AUTOSAR XML (schema 00053)
package /MICROSAR/Dcm_swc
  mode declaration group DcmEcuReset: category=EXPLICIT_ORDER, initial-mode=NONE, on-transition-value=7
    7 x mode:
      NONE: value=0
      HARD: value=1
      KEYONOFF: value=2
      SOFT: value=3
      JUMPTOBOOTLOADER: value=4
      JUMPTOSYSSUPPLIERBOOTLOADER: value=5
      EXECUTE: value=6
  mode declaration group DcmDiagnosticSessionControl: category=EXPLICIT_ORDER, initial-mode=DEFAULT_SESSION, on-transition-value=255
    mode DEFAULT_SESSION: value=1
    mode PROGRAMMING_SESSION: value=2
    mode EXTENDED_SESSION: value=3
  mode declaration group DcmCommunicationControl: category=EXPLICIT_ORDER, initial-mode=DCM_ENABLE_RX_TX_NORM, on-transition-value=12
    12 x mode:
      DCM_ENABLE_RX_TX_NORM: value=0
      DCM_ENABLE_RX_DISABLE_TX_NORM: value=1
      DCM_DISABLE_RX_ENABLE_TX_NORM: value=2
      DCM_DISABLE_RX_TX_NORMAL: value=3
      DCM_ENABLE_RX_TX_NM: value=4
      DCM_ENABLE_RX_DISABLE_TX_NM: value=5
      DCM_DISABLE_RX_ENABLE_TX_NM: value=6
      DCM_DISABLE_RX_TX_NM: value=7
      DCM_ENABLE_RX_TX_NORM_NM: value=8
      DCM_ENABLE_RX_DISABLE_TX_NORM_NM: value=9
      DCM_DISABLE_RX_ENABLE_TX_NORM_NM: value=10
      DCM_DISABLE_RX_TX_NORM_NM: value=11
  data type mapping set DcmMappingSet  # Contains mapping for ModeDeclarationGroups and data types which are provided by Dcm.
    mode-request-type-maps:
      implementation-data-type=Dcm_ControlDtcSettingType, mode-group=DcmControlDtcSetting
      implementation-data-type=Dcm_EcuResetType, mode-group=DcmEcuReset
      implementation-data-type=Dcm_DiagnosticSessionControlType, mode-group=DcmDiagnosticSessionControl
      implementation-data-type=Dcm_CommunicationModeType, mode-group=DcmCommunicationControl
package /MICROSAR/Dcm_swc/Interfaces
  mode switch interface DcmEcuReset: is-service=true, service-kind=DIAGNOSTIC-COMMUNICATION-MANAGER
    mode group DcmEcuReset: type=DcmEcuReset
  mode switch interface DcmDiagnosticSessionControl: is-service=true, service-kind=DIAGNOSTIC-COMMUNICATION-MANAGER
    mode group DcmDiagnosticSessionControl: type=DcmDiagnosticSessionControl
  mode switch interface DcmCommunicationControl_ComMConf_ComMChannel_CN_PCAN_RADAR_458ff0f1: is-service=true, service-kind=DIAGNOSTIC-COMMUNICATION-MANAGER
    mode group DcmCommunicationControl_ComMConf_ComMChannel_CN_PCAN_RADAR_458ff0f1: type=DcmCommunicationControl
  42 x client server interface, all with is-service=true, service-kind=DIAGNOSTIC-COMMUNICATION-MANAGER:
    DCMServices
      6 x operation:
        GetActiveProtocol: possible-error=E_OK
          arg ActiveProtocol: type=Dcm_ProtocolType, direction=OUT
        GetSesCtrlType: possible-error=E_OK
          arg SesCtrlType: type=Dcm_SesCtrlType, direction=OUT
        ResetToDefaultSession: possible-error=E_OK
        GetSecurityLevel: possible-error=E_OK
          arg SecLevel: type=Dcm_SecLevelType, direction=OUT
        SetActiveDiagnostic: possible-error=E_OK
          arg active: type=boolean, direction=IN
        GetRequestKind: possible-error=DCMServices/E_NOT_OK
          arg TesterSourceAddress: type=uint16, direction=IN
          arg RequestKind: type=Dcm_RequestKindType, direction=OUT
      error E_OK: error-code=0
      error E_NOT_OK: error-code=1
    SecurityAccess_UnlockedL1
      4 x operation:
        GetSeed: possible-error=[SecurityAccess_UnlockedL1/E_NOT_OK, SecurityAccess_UnlockedL1/DCM_E_PENDING]
          arg OpStatus: type=Dcm_OpStatusType, direction=IN
          arg Seed: type=Dcm_Data16ByteType, direction=OUT
          arg ErrorCode: type=Dcm_NegativeResponseCodeType, direction=OUT
        CompareKey: possible-error=[SecurityAccess_UnlockedL1/E_NOT_OK, SecurityAccess_UnlockedL1/DCM_E_PENDING, DCM_E_COMPARE_KEY_FAILED]
          arg Key: type=Dcm_Data16ByteType, direction=IN
          arg OpStatus: type=Dcm_OpStatusType, direction=IN
          arg ErrorCode: type=Dcm_NegativeResponseCodeType, direction=OUT
        GetSecurityAttemptCounter: possible-error=[SecurityAccess_UnlockedL1/E_NOT_OK, SecurityAccess_UnlockedL1/DCM_E_PENDING]
          arg OpStatus: type=Dcm_OpStatusType, direction=IN
          arg AttemptCounter: type=uint8, direction=OUT
        SetSecurityAttemptCounter: possible-error=[SecurityAccess_UnlockedL1/E_NOT_OK, SecurityAccess_UnlockedL1/DCM_E_PENDING]
          arg OpStatus: type=Dcm_OpStatusType, direction=IN
          arg AttemptCounter: type=uint8, direction=IN
      error E_NOT_OK: error-code=1
      error DCM_E_PENDING: error-code=10
      error DCM_E_COMPARE_KEY_FAILED: error-code=11
    DataServices_Data_VIN_Read
      operation ReadData: possible-error=[DataServices_Data_VIN_Read/E_NOT_OK, DataServices_Data_VIN_Read/DCM_E_PENDING]
        arg OpStatus: type=Dcm_OpStatusType, direction=IN
        arg Data: type=Dcm_DataElement_Data_VIN_ReadType, direction=OUT
      operation ConditionCheckRead: possible-error=[DataServices_Data_VIN_Read/E_NOT_OK, DataServices_Data_VIN_Read/DCM_E_PENDING]
        arg OpStatus: type=Dcm_OpStatusType, direction=IN
        arg ErrorCode: type=Dcm_NegativeResponseCodeType, direction=OUT
      operation WriteData: possible-error=[DataServices_Data_VIN_Read/E_NOT_OK, DataServices_Data_VIN_Read/DCM_E_PENDING]
        arg Data: type=Dcm_DataElement_Data_VIN_ReadType, direction=IN
        arg OpStatus: type=Dcm_OpStatusType, direction=IN
        arg ErrorCode: type=Dcm_NegativeResponseCodeType, direction=OUT
      error E_NOT_OK: error-code=1
      error DCM_E_PENDING: error-code=10
    RoutineServices_Routine_CheckProgPreCond_Start
      operation Start: possible-error=[RoutineServices_Routine_CheckProgPreCond_Start/E_NOT_OK, RoutineServices_Routine_CheckProgPreCond_Start/DCM_E_PENDING, RoutineServices_Routine_CheckProgPreCond_Start/DCM_E_FORCE_RCRRP]
        arg OpStatus: type=Dcm_OpStatusType, direction=IN
        arg Out_ResData: type=Dcm_StartDataOut_Routine_CheckProgPreCond_Start_Out_ResDataType, direction=OUT
        arg ErrorCode: type=Dcm_NegativeResponseCodeType, direction=OUT
      error E_NOT_OK: error-code=1
      error DCM_E_PENDING: error-code=10
      error DCM_E_FORCE_RCRRP: error-code=12
    RoutineServices_Routine_CheckSig_Start
      operation Start: possible-error=[RoutineServices_Routine_CheckSig_Start/E_NOT_OK, RoutineServices_Routine_CheckSig_Start/DCM_E_PENDING, RoutineServices_Routine_CheckSig_Start/DCM_E_FORCE_RCRRP]
        arg OpStatus: type=Dcm_OpStatusType, direction=IN
        arg Out_ResData: type=Dcm_StartDataOut_Routine_CheckSig_Start_Out_ResDataType, direction=OUT
        arg ErrorCode: type=Dcm_NegativeResponseCodeType, direction=OUT
      error E_NOT_OK: error-code=1
      error DCM_E_PENDING: error-code=10
      error DCM_E_FORCE_RCRRP: error-code=12
    RoutineServices_Routine_Static_Alignment_Execution_Start
      operation Start: possible-error=[RoutineServices_Routine_Static_Alignment_Execution_Start/E_NOT_OK, RoutineServices_Routine_Static_Alignment_Execution_Start/DCM_E_PENDING, RoutineServices_Routine_Static_Alignment_Execution_Start/DCM_E_FORCE_RCRRP]
        arg OpStatus: type=Dcm_OpStatusType, direction=IN
        arg ErrorCode: type=Dcm_NegativeResponseCodeType, direction=OUT
      operation Stop: possible-error=[RoutineServices_Routine_Static_Alignment_Execution_Start/E_NOT_OK, RoutineServices_Routine_Static_Alignment_Execution_Start/DCM_E_PENDING, RoutineServices_Routine_Static_Alignment_Execution_Start/DCM_E_FORCE_RCRRP]
        arg OpStatus: type=Dcm_OpStatusType, direction=IN
        arg ErrorCode: type=Dcm_NegativeResponseCodeType, direction=OUT
      operation RequestResults: possible-error=[RoutineServices_Routine_Static_Alignment_Execution_Start/E_NOT_OK, RoutineServices_Routine_Static_Alignment_Execution_Start/DCM_E_PENDING, RoutineServices_Routine_Static_Alignment_Execution_Start/DCM_E_FORCE_RCRRP]
        arg OpStatus: type=Dcm_OpStatusType, direction=IN
        arg Out_ResData: type=Dcm_RequestDataOut_Routine_Static_Alignment_Execution_Start_Out_ResDataType, direction=OUT
        arg ErrorCode: type=Dcm_NegativeResponseCodeType, direction=OUT
      error E_NOT_OK: error-code=1
      error DCM_E_PENDING: error-code=10
      error DCM_E_FORCE_RCRRP: error-code=12
    RoutineServices_Routine_Service_Alignment_Execution_Start
      operation Start: possible-error=[RoutineServices_Routine_Service_Alignment_Execution_Start/E_NOT_OK, RoutineServices_Routine_Service_Alignment_Execution_Start/DCM_E_PENDING, RoutineServices_Routine_Service_Alignment_Execution_Start/DCM_E_FORCE_RCRRP]
        arg OpStatus: type=Dcm_OpStatusType, direction=IN
        arg ErrorCode: type=Dcm_NegativeResponseCodeType, direction=OUT
      operation Stop: possible-error=[RoutineServices_Routine_Service_Alignment_Execution_Start/E_NOT_OK, RoutineServices_Routine_Service_Alignment_Execution_Start/DCM_E_PENDING, RoutineServices_Routine_Service_Alignment_Execution_Start/DCM_E_FORCE_RCRRP]
        arg OpStatus: type=Dcm_OpStatusType, direction=IN
        arg ErrorCode: type=Dcm_NegativeResponseCodeType, direction=OUT
      operation RequestResults: possible-error=[RoutineServices_Routine_Service_Alignment_Execution_Start/E_NOT_OK, RoutineServices_Routine_Service_Alignment_Execution_Start/DCM_E_PENDING, RoutineServices_Routine_Service_Alignment_Execution_Start/DCM_E_FORCE_RCRRP]
        arg OpStatus: type=Dcm_OpStatusType, direction=IN
        arg Out_ResData: type=Dcm_RequestDataOut_Routine_Service_Alignment_Execution_Start_Out_ResDataType, direction=OUT
        arg ErrorCode: type=Dcm_NegativeResponseCodeType, direction=OUT
      error E_NOT_OK: error-code=1
      error DCM_E_PENDING: error-code=10
      error DCM_E_FORCE_RCRRP: error-code=12
    RoutineServices_Routine_Pin_Position_Lock_Start
      operation Start: possible-error=[RoutineServices_Routine_Pin_Position_Lock_Start/E_NOT_OK, RoutineServices_Routine_Pin_Position_Lock_Start/DCM_E_PENDING, RoutineServices_Routine_Pin_Position_Lock_Start/DCM_E_FORCE_RCRRP]
        4 x arg:
          In_ReqData: type=Dcm_StartDataIn_Routine_Pin_Position_Lock_Start_In_ReqDataType, direction=IN
          OpStatus: type=Dcm_OpStatusType, direction=IN
          Out_ResData: type=Dcm_StartDataOut_Routine_Pin_Position_Lock_Start_Out_ResDataType, direction=OUT
          ErrorCode: type=Dcm_NegativeResponseCodeType, direction=OUT
      operation RequestResults: possible-error=[RoutineServices_Routine_Pin_Position_Lock_Start/E_NOT_OK, RoutineServices_Routine_Pin_Position_Lock_Start/DCM_E_PENDING, RoutineServices_Routine_Pin_Position_Lock_Start/DCM_E_FORCE_RCRRP]
        arg OpStatus: type=Dcm_OpStatusType, direction=IN
        arg Out_ResData: type=Dcm_RequestDataOut_Routine_Pin_Position_Lock_Start_Out_ResDataType, direction=OUT
        arg ErrorCode: type=Dcm_NegativeResponseCodeType, direction=OUT
      error E_NOT_OK: error-code=1
      error DCM_E_PENDING: error-code=10
      error DCM_E_FORCE_RCRRP: error-code=12
    RoutineServices_Routine_Pin_Position_Unlock_Start
      operation Start: possible-error=[RoutineServices_Routine_Pin_Position_Unlock_Start/E_NOT_OK, RoutineServices_Routine_Pin_Position_Unlock_Start/DCM_E_PENDING, RoutineServices_Routine_Pin_Position_Unlock_Start/DCM_E_FORCE_RCRRP]
        4 x arg:
          In_ReqData: type=Dcm_StartDataIn_Routine_Pin_Position_Unlock_Start_In_ReqDataType, direction=IN
          OpStatus: type=Dcm_OpStatusType, direction=IN
          Out_ResData: type=Dcm_StartDataOut_Routine_Pin_Position_Unlock_Start_Out_ResDataType, direction=OUT
          ErrorCode: type=Dcm_NegativeResponseCodeType, direction=OUT
      operation RequestResults: possible-error=[RoutineServices_Routine_Pin_Position_Unlock_Start/E_NOT_OK, RoutineServices_Routine_Pin_Position_Unlock_Start/DCM_E_PENDING, RoutineServices_Routine_Pin_Position_Unlock_Start/DCM_E_FORCE_RCRRP]
        arg OpStatus: type=Dcm_OpStatusType, direction=IN
        arg Out_ResData: type=Dcm_RequestDataOut_Routine_Pin_Position_Unlock_Start_Out_ResDataType, direction=OUT
        arg ErrorCode: type=Dcm_NegativeResponseCodeType, direction=OUT
      error E_NOT_OK: error-code=1
      error DCM_E_PENDING: error-code=10
      error DCM_E_FORCE_RCRRP: error-code=12
    RoutineServices_Routine_EraseMem_Start
      operation Start: possible-error=[RoutineServices_Routine_EraseMem_Start/E_NOT_OK, RoutineServices_Routine_EraseMem_Start/DCM_E_PENDING, RoutineServices_Routine_EraseMem_Start/DCM_E_FORCE_RCRRP]
        4 x arg:
          In_ReqData: type=Dcm_StartDataIn_Routine_EraseMem_Start_In_ReqDataType, direction=IN
          OpStatus: type=Dcm_OpStatusType, direction=IN
          Out_ResData: type=Dcm_StartDataOut_Routine_EraseMem_Start_Out_ResDataType, direction=OUT
          ErrorCode: type=Dcm_NegativeResponseCodeType, direction=OUT
      error E_NOT_OK: error-code=1
      error DCM_E_PENDING: error-code=10
      error DCM_E_FORCE_RCRRP: error-code=12
    RoutineServices_Routine_CheckProgDep_Start
      operation Start: possible-error=[RoutineServices_Routine_CheckProgDep_Start/E_NOT_OK, RoutineServices_Routine_CheckProgDep_Start/DCM_E_PENDING, RoutineServices_Routine_CheckProgDep_Start/DCM_E_FORCE_RCRRP]
        arg OpStatus: type=Dcm_OpStatusType, direction=IN
        arg Out_ResData: type=Dcm_StartDataOut_Routine_CheckProgDep_Start_Out_ResDataType, direction=OUT
        arg ErrorCode: type=Dcm_NegativeResponseCodeType, direction=OUT
      error E_NOT_OK: error-code=1
      error DCM_E_PENDING: error-code=10
      error DCM_E_FORCE_RCRRP: error-code=12
    DataServices_Data_ECUBuildDate_Read
      operation ReadData: possible-error=[DataServices_Data_ECUBuildDate_Read/E_NOT_OK, DataServices_Data_ECUBuildDate_Read/DCM_E_PENDING]
        arg OpStatus: type=Dcm_OpStatusType, direction=IN
        arg Data: type=Dcm_DataElement_Data_ECUBuildDate_ReadType, direction=OUT
      operation ConditionCheckRead: possible-error=[DataServices_Data_ECUBuildDate_Read/E_NOT_OK, DataServices_Data_ECUBuildDate_Read/DCM_E_PENDING]
        arg OpStatus: type=Dcm_OpStatusType, direction=IN
        arg ErrorCode: type=Dcm_NegativeResponseCodeType, direction=OUT
      error E_NOT_OK: error-code=1
      error DCM_E_PENDING: error-code=10
    DataServices_Data_Static_Alignment_Engineering_Write_Configuration_Parameter_Write
      operation WriteData: possible-error=[DataServices_Data_Static_Alignment_Engineering_Write_Configuration_Parameter_Write/E_NOT_OK, DataServices_Data_Static_Alignment_Engineering_Write_Configuration_Parameter_Write/DCM_E_PENDING]
        arg Data: type=Dcm_DataElement_Data_Static_Alignment_Engineering_Write_Configuration_Parameter_WriteType, direction=IN
        arg OpStatus: type=Dcm_OpStatusType, direction=IN
        arg ErrorCode: type=Dcm_NegativeResponseCodeType, direction=OUT
      error E_NOT_OK: error-code=1
      error DCM_E_PENDING: error-code=10
    DataServices_Data_CANDBMatrixVer_Read
      operation ReadData: possible-error=[DataServices_Data_CANDBMatrixVer_Read/E_NOT_OK, DataServices_Data_CANDBMatrixVer_Read/DCM_E_PENDING]
        arg OpStatus: type=Dcm_OpStatusType, direction=IN
        arg Data: type=Dcm_DataElement_Data_CANDBMatrixVer_ReadType, direction=OUT
      operation ConditionCheckRead: possible-error=[DataServices_Data_CANDBMatrixVer_Read/E_NOT_OK, DataServices_Data_CANDBMatrixVer_Read/DCM_E_PENDING]
        arg OpStatus: type=Dcm_OpStatusType, direction=IN
        arg ErrorCode: type=Dcm_NegativeResponseCodeType, direction=OUT
      error E_NOT_OK: error-code=1
      error DCM_E_PENDING: error-code=10
    DataServices_Data_Service_Alignment_Engineering_Non_Configuration_Parameters_Read
      operation ReadData: possible-error=[DataServices_Data_Service_Alignment_Engineering_Non_Configuration_Parameters_Read/E_NOT_OK, DataServices_Data_Service_Alignment_Engineering_Non_Configuration_Parameters_Read/DCM_E_PENDING]
        arg OpStatus: type=Dcm_OpStatusType, direction=IN
        arg Data: type=Dcm_DataElement_Data_Service_Alignment_Engineering_Non_Configuration_Parameters_ReadType, direction=OUT
      operation ConditionCheckRead: possible-error=[DataServices_Data_Service_Alignment_Engineering_Non_Configuration_Parameters_Read/E_NOT_OK, DataServices_Data_Service_Alignment_Engineering_Non_Configuration_Parameters_Read/DCM_E_PENDING]
        arg OpStatus: type=Dcm_OpStatusType, direction=IN
        arg ErrorCode: type=Dcm_NegativeResponseCodeType, direction=OUT
      error E_NOT_OK: error-code=1
      error DCM_E_PENDING: error-code=10
    DataServices_Data_Sensor_Availability_Flag_Read
      operation ReadData: possible-error=[DataServices_Data_Sensor_Availability_Flag_Read/E_NOT_OK, DataServices_Data_Sensor_Availability_Flag_Read/DCM_E_PENDING]
        arg OpStatus: type=Dcm_OpStatusType, direction=IN
        arg Data: type=Dcm_DataElement_Data_Sensor_Availability_Flag_ReadType, direction=OUT
      operation ConditionCheckRead: possible-error=[DataServices_Data_Sensor_Availability_Flag_Read/E_NOT_OK, DataServices_Data_Sensor_Availability_Flag_Read/DCM_E_PENDING]
        arg OpStatus: type=Dcm_OpStatusType, direction=IN
        arg ErrorCode: type=Dcm_NegativeResponseCodeType, direction=OUT
      error E_NOT_OK: error-code=1
      error DCM_E_PENDING: error-code=10
    DataServices_Data_Read_Active_Fault_Table_Read
      operation ReadData: possible-error=[DataServices_Data_Read_Active_Fault_Table_Read/E_NOT_OK, DataServices_Data_Read_Active_Fault_Table_Read/DCM_E_PENDING]
        arg OpStatus: type=Dcm_OpStatusType, direction=IN
        arg Data: type=Dcm_DataElement_Data_Read_Active_Fault_Table_ReadType, direction=OUT
      operation ConditionCheckRead: possible-error=[DataServices_Data_Read_Active_Fault_Table_Read/E_NOT_OK, DataServices_Data_Read_Active_Fault_Table_Read/DCM_E_PENDING]
        arg OpStatus: type=Dcm_OpStatusType, direction=IN
        arg ErrorCode: type=Dcm_NegativeResponseCodeType, direction=OUT
      error E_NOT_OK: error-code=1
      error DCM_E_PENDING: error-code=10
    DataServices_Data_Static_Alignment_Engineering_Non_Configuration_Parameters_Read
      operation ReadData: possible-error=[DataServices_Data_Static_Alignment_Engineering_Non_Configuration_Parameters_Read/E_NOT_OK, DataServices_Data_Static_Alignment_Engineering_Non_Configuration_Parameters_Read/DCM_E_PENDING]
        arg OpStatus: type=Dcm_OpStatusType, direction=IN
        arg Data: type=Dcm_DataElement_Data_Static_Alignment_Engineering_Non_Configuration_Parameters_ReadType, direction=OUT
      operation ConditionCheckRead: possible-error=[DataServices_Data_Static_Alignment_Engineering_Non_Configuration_Parameters_Read/E_NOT_OK, DataServices_Data_Static_Alignment_Engineering_Non_Configuration_Parameters_Read/DCM_E_PENDING]
        arg OpStatus: type=Dcm_OpStatusType, direction=IN
        arg ErrorCode: type=Dcm_NegativeResponseCodeType, direction=OUT
      error E_NOT_OK: error-code=1
      error DCM_E_PENDING: error-code=10
    DataServices_Data_Dataset_Part_No_and_Revision_Read
      operation ReadData: possible-error=[DataServices_Data_Dataset_Part_No_and_Revision_Read/E_NOT_OK, DataServices_Data_Dataset_Part_No_and_Revision_Read/DCM_E_PENDING]
        arg OpStatus: type=Dcm_OpStatusType, direction=IN
        arg Data: type=Dcm_DataElement_Data_Dataset_Part_No_and_Revision_ReadType, direction=OUT
      operation ConditionCheckRead: possible-error=[DataServices_Data_Dataset_Part_No_and_Revision_Read/E_NOT_OK, DataServices_Data_Dataset_Part_No_and_Revision_Read/DCM_E_PENDING]
        arg OpStatus: type=Dcm_OpStatusType, direction=IN
        arg ErrorCode: type=Dcm_NegativeResponseCodeType, direction=OUT
      error E_NOT_OK: error-code=1
      error DCM_E_PENDING: error-code=10
    DataServices_Data_HardwareNumber_Read
      operation ReadData: possible-error=[DataServices_Data_HardwareNumber_Read/E_NOT_OK, DataServices_Data_HardwareNumber_Read/DCM_E_PENDING]
        arg OpStatus: type=Dcm_OpStatusType, direction=IN
        arg Data: type=Dcm_DataElement_Data_HardwareNumber_ReadType, direction=OUT
      operation ConditionCheckRead: possible-error=[DataServices_Data_HardwareNumber_Read/E_NOT_OK, DataServices_Data_HardwareNumber_Read/DCM_E_PENDING]
        arg OpStatus: type=Dcm_OpStatusType, direction=IN
        arg ErrorCode: type=Dcm_NegativeResponseCodeType, direction=OUT
      error E_NOT_OK: error-code=1
      error DCM_E_PENDING: error-code=10
    DataServices_Data_Vehicle_Variant_Read
      operation ReadData: possible-error=[DataServices_Data_Vehicle_Variant_Read/E_NOT_OK, DataServices_Data_Vehicle_Variant_Read/DCM_E_PENDING]
        arg OpStatus: type=Dcm_OpStatusType, direction=IN
        arg Data: type=Dcm_DataElement_Data_Vehicle_Variant_ReadType, direction=OUT
      operation ConditionCheckRead: possible-error=[DataServices_Data_Vehicle_Variant_Read/E_NOT_OK, DataServices_Data_Vehicle_Variant_Read/DCM_E_PENDING]
        arg OpStatus: type=Dcm_OpStatusType, direction=IN
        arg ErrorCode: type=Dcm_NegativeResponseCodeType, direction=OUT
      error E_NOT_OK: error-code=1
      error DCM_E_PENDING: error-code=10
    DataServices_Data_Static_Alignment_Result_Parameters_Read
      operation ReadData: possible-error=[DataServices_Data_Static_Alignment_Result_Parameters_Read/E_NOT_OK, DataServices_Data_Static_Alignment_Result_Parameters_Read/DCM_E_PENDING]
        arg OpStatus: type=Dcm_OpStatusType, direction=IN
        arg Data: type=Dcm_DataElement_Data_Static_Alignment_Result_Parameters_ReadType, direction=OUT
      operation ConditionCheckRead: possible-error=[DataServices_Data_Static_Alignment_Result_Parameters_Read/E_NOT_OK, DataServices_Data_Static_Alignment_Result_Parameters_Read/DCM_E_PENDING]
        arg OpStatus: type=Dcm_OpStatusType, direction=IN
        arg ErrorCode: type=Dcm_NegativeResponseCodeType, direction=OUT
      error E_NOT_OK: error-code=1
      error DCM_E_PENDING: error-code=10
    DataServices_Data_Base_Software_Version_number_Read
      operation ReadData: possible-error=[DataServices_Data_Base_Software_Version_number_Read/E_NOT_OK, DataServices_Data_Base_Software_Version_number_Read/DCM_E_PENDING]
        arg OpStatus: type=Dcm_OpStatusType, direction=IN
        arg Data: type=Dcm_DataElement_Data_Base_Software_Version_number_ReadType, direction=OUT
      operation ConditionCheckRead: possible-error=[DataServices_Data_Base_Software_Version_number_Read/E_NOT_OK, DataServices_Data_Base_Software_Version_number_Read/DCM_E_PENDING]
        arg OpStatus: type=Dcm_OpStatusType, direction=IN
        arg ErrorCode: type=Dcm_NegativeResponseCodeType, direction=OUT
      error E_NOT_OK: error-code=1
      error DCM_E_PENDING: error-code=10
    DataServices_Data_VehicleSpeed_Read
      operation ReadData: possible-error=[DataServices_Data_VehicleSpeed_Read/E_NOT_OK, DataServices_Data_VehicleSpeed_Read/DCM_E_PENDING]
        arg OpStatus: type=Dcm_OpStatusType, direction=IN
        arg Data: type=Dcm_DataElement_Data_VehicleSpeed_ReadType, direction=OUT
      operation ConditionCheckRead: possible-error=[DataServices_Data_VehicleSpeed_Read/E_NOT_OK, DataServices_Data_VehicleSpeed_Read/DCM_E_PENDING]
        arg OpStatus: type=Dcm_OpStatusType, direction=IN
        arg ErrorCode: type=Dcm_NegativeResponseCodeType, direction=OUT
      error E_NOT_OK: error-code=1
      error DCM_E_PENDING: error-code=10
    DataServices_Data_Software_Fingerprint_Read
      operation ReadData: possible-error=[DataServices_Data_Software_Fingerprint_Read/E_NOT_OK, DataServices_Data_Software_Fingerprint_Read/DCM_E_PENDING]
        arg OpStatus: type=Dcm_OpStatusType, direction=IN
        arg Data: type=Dcm_DataElement_Data_Software_Fingerprint_ReadType, direction=OUT
      operation ConditionCheckRead: possible-error=[DataServices_Data_Software_Fingerprint_Read/E_NOT_OK, DataServices_Data_Software_Fingerprint_Read/DCM_E_PENDING]
        arg OpStatus: type=Dcm_OpStatusType, direction=IN
        arg ErrorCode: type=Dcm_NegativeResponseCodeType, direction=OUT
      operation WriteData: possible-error=[DataServices_Data_Software_Fingerprint_Read/E_NOT_OK, DataServices_Data_Software_Fingerprint_Read/DCM_E_PENDING]
        arg Data: type=Dcm_DataElement_Data_Software_Fingerprint_ReadType, direction=IN
        arg OpStatus: type=Dcm_OpStatusType, direction=IN
        arg ErrorCode: type=Dcm_NegativeResponseCodeType, direction=OUT
      error E_NOT_OK: error-code=1
      error DCM_E_PENDING: error-code=10
    DataServices_Data_Ego_Acceleration_Read
      operation ReadData: possible-error=[DataServices_Data_Ego_Acceleration_Read/E_NOT_OK, DataServices_Data_Ego_Acceleration_Read/DCM_E_PENDING]
        arg OpStatus: type=Dcm_OpStatusType, direction=IN
        arg Data: type=Dcm_DataElement_Data_Ego_Acceleration_ReadType, direction=OUT
      operation ConditionCheckRead: possible-error=[DataServices_Data_Ego_Acceleration_Read/E_NOT_OK, DataServices_Data_Ego_Acceleration_Read/DCM_E_PENDING]
        arg OpStatus: type=Dcm_OpStatusType, direction=IN
        arg ErrorCode: type=Dcm_NegativeResponseCodeType, direction=OUT
      error E_NOT_OK: error-code=1
      error DCM_E_PENDING: error-code=10
    DataServices_Data_Static_Alignment_Engineering_Read_Parameters_Read
      operation ReadData: possible-error=[DataServices_Data_Static_Alignment_Engineering_Read_Parameters_Read/E_NOT_OK, DataServices_Data_Static_Alignment_Engineering_Read_Parameters_Read/DCM_E_PENDING]
        arg OpStatus: type=Dcm_OpStatusType, direction=IN
        arg Data: type=Dcm_DataElement_Data_Static_Alignment_Engineering_Read_Parameters_ReadType, direction=OUT
      operation ConditionCheckRead: possible-error=[DataServices_Data_Static_Alignment_Engineering_Read_Parameters_Read/E_NOT_OK, DataServices_Data_Static_Alignment_Engineering_Read_Parameters_Read/DCM_E_PENDING]
        arg OpStatus: type=Dcm_OpStatusType, direction=IN
        arg ErrorCode: type=Dcm_NegativeResponseCodeType, direction=OUT
      error E_NOT_OK: error-code=1
      error DCM_E_PENDING: error-code=10
    DataServices_Data_BootloaderNumber_Read
      operation ReadData: possible-error=[DataServices_Data_BootloaderNumber_Read/E_NOT_OK, DataServices_Data_BootloaderNumber_Read/DCM_E_PENDING]
        arg OpStatus: type=Dcm_OpStatusType, direction=IN
        arg Data: type=Dcm_DataElement_Data_BootloaderNumber_ReadType, direction=OUT
      operation ConditionCheckRead: possible-error=[DataServices_Data_BootloaderNumber_Read/E_NOT_OK, DataServices_Data_BootloaderNumber_Read/DCM_E_PENDING]
        arg OpStatus: type=Dcm_OpStatusType, direction=IN
        arg ErrorCode: type=Dcm_NegativeResponseCodeType, direction=OUT
      error E_NOT_OK: error-code=1
      error DCM_E_PENDING: error-code=10
    DataServices_Data_ECUVoltage_Read
      operation ReadData: possible-error=[DataServices_Data_ECUVoltage_Read/E_NOT_OK, DataServices_Data_ECUVoltage_Read/DCM_E_PENDING]
        arg OpStatus: type=Dcm_OpStatusType, direction=IN
        arg Data: type=Dcm_DataElement_Data_ECUVoltage_ReadType, direction=OUT
      operation ConditionCheckRead: possible-error=[DataServices_Data_ECUVoltage_Read/E_NOT_OK, DataServices_Data_ECUVoltage_Read/DCM_E_PENDING]
        arg OpStatus: type=Dcm_OpStatusType, direction=IN
        arg ErrorCode: type=Dcm_NegativeResponseCodeType, direction=OUT
      error E_NOT_OK: error-code=1
      error DCM_E_PENDING: error-code=10
    DataServices_Data_Boot_App_Identification_DID_Read
      operation ReadData: possible-error=[DataServices_Data_Boot_App_Identification_DID_Read/E_NOT_OK, DataServices_Data_Boot_App_Identification_DID_Read/DCM_E_PENDING]
        arg OpStatus: type=Dcm_OpStatusType, direction=IN
        arg Data: type=Dcm_DataElement_Data_Boot_App_Identification_DID_ReadType, direction=OUT
      operation ConditionCheckRead: possible-error=[DataServices_Data_Boot_App_Identification_DID_Read/E_NOT_OK, DataServices_Data_Boot_App_Identification_DID_Read/DCM_E_PENDING]
        arg OpStatus: type=Dcm_OpStatusType, direction=IN
        arg ErrorCode: type=Dcm_NegativeResponseCodeType, direction=OUT
      error E_NOT_OK: error-code=1
      error DCM_E_PENDING: error-code=10
    DataServices_Data_ActiveDiagnosticSessionDataIdentifier_Read
      operation ReadData: possible-error=[DataServices_Data_ActiveDiagnosticSessionDataIdentifier_Read/E_NOT_OK, DataServices_Data_ActiveDiagnosticSessionDataIdentifier_Read/DCM_E_PENDING]
        arg OpStatus: type=Dcm_OpStatusType, direction=IN
        arg Data: type=Dcm_DataElement_Data_ActiveDiagnosticSessionDataIdentifier_ReadType, direction=OUT
      operation ConditionCheckRead: possible-error=[DataServices_Data_ActiveDiagnosticSessionDataIdentifier_Read/E_NOT_OK, DataServices_Data_ActiveDiagnosticSessionDataIdentifier_Read/DCM_E_PENDING]
        arg OpStatus: type=Dcm_OpStatusType, direction=IN
        arg ErrorCode: type=Dcm_NegativeResponseCodeType, direction=OUT
      error E_NOT_OK: error-code=1
      error DCM_E_PENDING: error-code=10
    DataServices_Data_Hardware_Version_number_Read
      operation ReadData: possible-error=[DataServices_Data_Hardware_Version_number_Read/E_NOT_OK, DataServices_Data_Hardware_Version_number_Read/DCM_E_PENDING]
        arg OpStatus: type=Dcm_OpStatusType, direction=IN
        arg Data: type=Dcm_DataElement_Data_Hardware_Version_number_ReadType, direction=OUT
      operation ConditionCheckRead: possible-error=[DataServices_Data_Hardware_Version_number_Read/E_NOT_OK, DataServices_Data_Hardware_Version_number_Read/DCM_E_PENDING]
        arg OpStatus: type=Dcm_OpStatusType, direction=IN
        arg ErrorCode: type=Dcm_NegativeResponseCodeType, direction=OUT
      error E_NOT_OK: error-code=1
      error DCM_E_PENDING: error-code=10
    DataServices_Data_Manual_Alignment_Execution_Read
      operation ReadData: possible-error=[DataServices_Data_Manual_Alignment_Execution_Read/E_NOT_OK, DataServices_Data_Manual_Alignment_Execution_Read/DCM_E_PENDING]
        arg OpStatus: type=Dcm_OpStatusType, direction=IN
        arg Data: type=Dcm_DataElement_Data_Manual_Alignment_Execution_ReadType, direction=OUT
      operation ConditionCheckRead: possible-error=[DataServices_Data_Manual_Alignment_Execution_Read/E_NOT_OK, DataServices_Data_Manual_Alignment_Execution_Read/DCM_E_PENDING]
        arg OpStatus: type=Dcm_OpStatusType, direction=IN
        arg ErrorCode: type=Dcm_NegativeResponseCodeType, direction=OUT
      operation WriteData: possible-error=[DataServices_Data_Manual_Alignment_Execution_Read/E_NOT_OK, DataServices_Data_Manual_Alignment_Execution_Read/DCM_E_PENDING]
        arg Data: type=Dcm_DataElement_Data_Manual_Alignment_Execution_ReadType, direction=IN
        arg OpStatus: type=Dcm_OpStatusType, direction=IN
        arg ErrorCode: type=Dcm_NegativeResponseCodeType, direction=OUT
      error E_NOT_OK: error-code=1
      error DCM_E_PENDING: error-code=10
    DataServices_Data_SerialNumber_Read
      operation ReadData: possible-error=[DataServices_Data_SerialNumber_Read/E_NOT_OK, DataServices_Data_SerialNumber_Read/DCM_E_PENDING]
        arg OpStatus: type=Dcm_OpStatusType, direction=IN
        arg Data: type=Dcm_DataElement_Data_SerialNumber_ReadType, direction=OUT
      operation ConditionCheckRead: possible-error=[DataServices_Data_SerialNumber_Read/E_NOT_OK, DataServices_Data_SerialNumber_Read/DCM_E_PENDING]
        arg OpStatus: type=Dcm_OpStatusType, direction=IN
        arg ErrorCode: type=Dcm_NegativeResponseCodeType, direction=OUT
      error E_NOT_OK: error-code=1
      error DCM_E_PENDING: error-code=10
    DataServices_Data_PCAN_DBC_Version_Read
      operation ReadData: possible-error=[DataServices_Data_PCAN_DBC_Version_Read/E_NOT_OK, DataServices_Data_PCAN_DBC_Version_Read/DCM_E_PENDING]
        arg OpStatus: type=Dcm_OpStatusType, direction=IN
        arg Data: type=Dcm_DataElement_Data_PCAN_DBC_Version_ReadType, direction=OUT
      operation ConditionCheckRead: possible-error=[DataServices_Data_PCAN_DBC_Version_Read/E_NOT_OK, DataServices_Data_PCAN_DBC_Version_Read/DCM_E_PENDING]
        arg OpStatus: type=Dcm_OpStatusType, direction=IN
        arg ErrorCode: type=Dcm_NegativeResponseCodeType, direction=OUT
      error E_NOT_OK: error-code=1
      error DCM_E_PENDING: error-code=10
    DataServices_Data_Auto_Alignment_Status_Information_Read
      operation ReadData: possible-error=[DataServices_Data_Auto_Alignment_Status_Information_Read/E_NOT_OK, DataServices_Data_Auto_Alignment_Status_Information_Read/DCM_E_PENDING]
        arg OpStatus: type=Dcm_OpStatusType, direction=IN
        arg Data: type=Dcm_DataElement_Data_Auto_Alignment_Status_Information_ReadType, direction=OUT
      operation ConditionCheckRead: possible-error=[DataServices_Data_Auto_Alignment_Status_Information_Read/E_NOT_OK, DataServices_Data_Auto_Alignment_Status_Information_Read/DCM_E_PENDING]
        arg OpStatus: type=Dcm_OpStatusType, direction=IN
        arg ErrorCode: type=Dcm_NegativeResponseCodeType, direction=OUT
      error E_NOT_OK: error-code=1
      error DCM_E_PENDING: error-code=10
    DataServices_Data_Service_Alignment_Result_Parameters_Read
      operation ReadData: possible-error=[DataServices_Data_Service_Alignment_Result_Parameters_Read/E_NOT_OK, DataServices_Data_Service_Alignment_Result_Parameters_Read/DCM_E_PENDING]
        arg OpStatus: type=Dcm_OpStatusType, direction=IN
        arg Data: type=Dcm_DataElement_Data_Service_Alignment_Result_Parameters_ReadType, direction=OUT
      operation ConditionCheckRead: possible-error=[DataServices_Data_Service_Alignment_Result_Parameters_Read/E_NOT_OK, DataServices_Data_Service_Alignment_Result_Parameters_Read/DCM_E_PENDING]
        arg OpStatus: type=Dcm_OpStatusType, direction=IN
        arg ErrorCode: type=Dcm_NegativeResponseCodeType, direction=OUT
      error E_NOT_OK: error-code=1
      error DCM_E_PENDING: error-code=10
    DataServices_Data_SMC_Part_No_and_Revision_Read
      operation ReadData: possible-error=[DataServices_Data_SMC_Part_No_and_Revision_Read/E_NOT_OK, DataServices_Data_SMC_Part_No_and_Revision_Read/DCM_E_PENDING]
        arg OpStatus: type=Dcm_OpStatusType, direction=IN
        arg Data: type=Dcm_DataElement_Data_SMC_Part_No_and_Revision_ReadType, direction=OUT
      operation ConditionCheckRead: possible-error=[DataServices_Data_SMC_Part_No_and_Revision_Read/E_NOT_OK, DataServices_Data_SMC_Part_No_and_Revision_Read/DCM_E_PENDING]
        arg OpStatus: type=Dcm_OpStatusType, direction=IN
        arg ErrorCode: type=Dcm_NegativeResponseCodeType, direction=OUT
      error E_NOT_OK: error-code=1
      error DCM_E_PENDING: error-code=10
    DataServices_Data_DateandTime_Read
      operation ReadData: possible-error=[DataServices_Data_DateandTime_Read/E_NOT_OK, DataServices_Data_DateandTime_Read/DCM_E_PENDING]
        arg OpStatus: type=Dcm_OpStatusType, direction=IN
        arg Data: type=Dcm_DataElement_Data_DateandTime_ReadType, direction=OUT
      operation ConditionCheckRead: possible-error=[DataServices_Data_DateandTime_Read/E_NOT_OK, DataServices_Data_DateandTime_Read/DCM_E_PENDING]
        arg OpStatus: type=Dcm_OpStatusType, direction=IN
        arg ErrorCode: type=Dcm_NegativeResponseCodeType, direction=OUT
      error E_NOT_OK: error-code=1
      error DCM_E_PENDING: error-code=10
    DataServices_Data_SoftwareNumber_Read
      operation ReadData: possible-error=[DataServices_Data_SoftwareNumber_Read/E_NOT_OK, DataServices_Data_SoftwareNumber_Read/DCM_E_PENDING]
        arg OpStatus: type=Dcm_OpStatusType, direction=IN
        arg Data: type=Dcm_DataElement_Data_SoftwareNumber_ReadType, direction=OUT
      operation ConditionCheckRead: possible-error=[DataServices_Data_SoftwareNumber_Read/E_NOT_OK, DataServices_Data_SoftwareNumber_Read/DCM_E_PENDING]
        arg OpStatus: type=Dcm_OpStatusType, direction=IN
        arg ErrorCode: type=Dcm_NegativeResponseCodeType, direction=OUT
      error E_NOT_OK: error-code=1
      error DCM_E_PENDING: error-code=10
    DataServices_Data_Pin_Position_Status_Read
      operation ReadData: possible-error=[DataServices_Data_Pin_Position_Status_Read/E_NOT_OK, DataServices_Data_Pin_Position_Status_Read/DCM_E_PENDING]
        arg OpStatus: type=Dcm_OpStatusType, direction=IN
        arg Data: type=Dcm_DataElement_Data_Pin_Position_Status_ReadType, direction=OUT
      operation ConditionCheckRead: possible-error=[DataServices_Data_Pin_Position_Status_Read/E_NOT_OK, DataServices_Data_Pin_Position_Status_Read/DCM_E_PENDING]
        arg OpStatus: type=Dcm_OpStatusType, direction=IN
        arg ErrorCode: type=Dcm_NegativeResponseCodeType, direction=OUT
      error E_NOT_OK: error-code=1
      error DCM_E_PENDING: error-code=10
    ServiceRequestNotification
      operation Indication: possible-error=[ServiceRequestNotification/E_NOT_OK, E_REQUEST_NOT_ACCEPTED]
        6 x arg:
          SID: type=uint8, direction=IN
          RequestData: type=Dcm_Data96ByteType, direction=IN
          DataSize: type=uint16, direction=IN
          ReqType: type=uint8, direction=IN
          SourceAddress: type=uint16, direction=IN
          ErrorCode: type=Dcm_NegativeResponseCodeType, direction=OUT
      operation Confirmation: possible-error=ServiceRequestNotification/E_NOT_OK
        4 x arg, all with direction=IN:
          SID: type=uint8
          ReqType: type=uint8
          SourceAddress: type=uint16
          ConfirmationStatus: type=Dcm_ConfirmationStatusType
      error E_NOT_OK: error-code=1
      error E_REQUEST_NOT_ACCEPTED: error-code=8
  mode switch interface DcmCommunicationControl_ComMConf_ComMChannel_CN_VCAN_RADAR_489180b6: is-service=true, service-kind=DIAGNOSTIC-COMMUNICATION-MANAGER
    mode group DcmCommunicationControl_ComMConf_ComMChannel_CN_VCAN_RADAR_489180b6: type=DcmCommunicationControl
package /MICROSAR/Dcm_swc/DataTypes
  102 x impl type:
    Dcm_ConfirmationStatusType: compu {0=DCM_RES_POS_OK, 1=DCM_RES_POS_NOT_OK, 2=DCM_RES_NEG_OK, 3=DCM_RES_NEG_NOT_OK}, range raw 0..3, implementation-data-type=uint8
    Dcm_OpStatusType: compu {0=DCM_INITIAL, 1=DCM_PENDING, 2=DCM_CANCEL, 3=DCM_FORCE_RCRRP_OK, 64=DCM_FORCE_RCRRP_NOT_OK}, range raw 0..64, implementation-data-type=uint8
    Dcm_NegativeResponseCodeType:
      compu {0=DCM_E_POSITIVERESPONSE, 16=DCM_E_GENERALREJECT, 17=DCM_E_SERVICENOTSUPPORTED, 18=DCM_E_SUBFUNCTIONNOTSUPPORTED, 19=DCM_E_INCORRECTMESSAGELENGTHORINVALIDFORMAT, 20=DCM_E_RESPONSETOOLONG, 33=DCM_E_BUSYREPEATREQUEST, 34=DCM_E_CONDITIONSNOTCORRECT, 36=DCM_E_REQUESTSEQUENCEERROR, 37=DCM_E_NORESPONSEFROMSUBNETCOMPONENT, 38=DCM_E_FAILUREPREVENTSEXECUTIONOFREQUESTEDACTION, 49=DCM_E_REQUESTOUTOFRANGE, 51=DCM_E_SECURITYACCESSDENIED, 52=DCM_E_AUTHENTICATIONREQUIRED, 53=DCM_E_INVALIDKEY, 54=DCM_E_EXCEEDNUMBEROFATTEMPTS, 55=DCM_E_REQUIREDTIMEDELAYNOTEXPIRED, 80=DCM_E_CVF_INVALIDTIMEPERIOD, 81=DCM_E_CVF_INVALIDSIGNATURE, 82=DCM_E_CVF_INVALIDCHAINOFTRUST, 83=DCM_E_CVF_INVALIDTYPE, 84=DCM_E_CVF_INVALIDFORMAT, 85=DCM_E_CVF_INVALIDCONTENT, 86=DCM_E_CVF_INVALIDSCOPE, 87=DCM_E_CVF_INVALIDCERTIFICATEREVOKED, 88=DCM_E_OWNERSHIPVERIFICATIONFAILED, 89=DCM_E_CHALLENGECALCULATIONFAILED, 112=DCM_E_UPLOADDOWNLOADNOTACCEPTED, 113=DCM_E_TRANSFERDATASUSPENDED, 114=DCM_E_GENERALPROGRAMMINGFAILURE, 115=DCM_E_WRONGBLOCKSEQUENCECOUNTER, 120=DCM_E_REQUESTCORRECTLYRECEIVEDRESPONSEPENDING, 126=DCM_E_SUBFUNCTIONNOTSUPPORTEDINACTIVESESSION, 127=DCM_E_SERVICENOTSUPPORTEDINACTIVESESSION, 129=DCM_E_RPMTOOHIGH, 130=DCM_E_RPMTOOLOW, 131=DCM_E_ENGINEISRUNNING, 132=DCM_E_ENGINEISNOTRUNNING, 133=DCM_E_ENGINERUNTIMETOOLOW, 134=DCM_E_TEMPERATURETOOHIGH, 135=DCM_E_TEMPERATURETOOLOW, 136=DCM_E_VEHICLESPEEDTOOHIGH, 137=DCM_E_VEHICLESPEEDTOOLOW, 138=DCM_E_THROTTLE_PEDALTOOHIGH, 139=DCM_E_THROTTLE_PEDALTOOLOW, 140=DCM_E_TRANSMISSIONRANGENOTINNEUTRAL, 141=DCM_E_TRANSMISSIONRANGENOTINGEAR, 143=DCM_E_BRAKESWITCH_NOTCLOSED, 144=DCM_E_SHIFTERLEVERNOTINPARK, 145=DCM_E_TORQUECONVERTERCLUTCHLOCKED, 146=DCM_E_VOLTAGETOOHIGH, 147=DCM_E_VOLTAGETOOLOW, 240..249=DCM_E_VMSCNC_0..DCM_E_VMSCNC_9, 250=DCM_E_VMSCNC_A, 251=DCM_E_VMSCNC_B, 252=DCM_E_VMSCNC_C, 253=DCM_E_VMSCNC_D, 254=DCM_E_VMSCNC_E}
      range raw 0..255
      implementation-data-type=uint8
    Dcm_ProtocolType: compu {0=DCM_OBD_ON_CAN, 1=DCM_OBD_ON_FLEXRAY, 2=DCM_OBD_ON_IP, 3=DCM_UDS_ON_CAN, 4=DCM_UDS_ON_FLEXRAY, 5=DCM_UDS_ON_IP, 12=DCM_NO_ACTIVE_PROTOCOL, 240..254=DCM_SUPPLIER_1..DCM_SUPPLIER_15}, range raw 0..254, implementation-data-type=uint8
    Dcm_RequestKindType: compu {0=DCM_REQ_KIND_NONE, 1=DCM_REQ_KIND_EXTERNAL, 2=DCM_REQ_KIND_ROE}, range raw 0..2, implementation-data-type=uint8
    Dcm_SesCtrlType: compu {1=DCM_DEFAULT_SESSION, 2=DCM_PROGRAMMING_SESSION, 3=DCM_EXTENDED_DIAGNOSTIC_SESSION}, range raw 0..3, implementation-data-type=uint8
    Dcm_ControlDtcSettingType: compu {0=DCM_ENUM_ENABLEDTCSETTING, 1=DCM_ENUM_DISABLEDTCSETTING}, range raw 0..255, implementation-data-type=uint8
    Dcm_EcuResetType: compu {0=DCM_ENUM_NONE, 1=DCM_ENUM_HARD, 2=DCM_ENUM_KEYONOFF, 3=DCM_ENUM_SOFT, 4=DCM_ENUM_JUMPTOBOOTLOADER, 5=DCM_ENUM_JUMPTOSYSSUPPLIERBOOTLOADER, 6=DCM_ENUM_EXECUTE}, range raw 0..255, implementation-data-type=uint8
    Dcm_DiagnosticSessionControlType: compu {1=DCM_ENUM_DEFAULT_SESSION, 2=DCM_ENUM_PROGRAMMING_SESSION, 3=DCM_ENUM_EXTENDED_SESSION}, range raw 0..255, implementation-data-type=uint8
    Dcm_CommunicationModeType:
      compu {0=DCM_ENABLE_RX_TX_NORM, 1=DCM_ENABLE_RX_DISABLE_TX_NORM, 2=DCM_DISABLE_RX_ENABLE_TX_NORM, 3=DCM_DISABLE_RX_TX_NORMAL, 4=DCM_ENABLE_RX_TX_NM, 5=DCM_ENABLE_RX_DISABLE_TX_NM, 6=DCM_DISABLE_RX_ENABLE_TX_NM, 7=DCM_DISABLE_RX_TX_NM, 8=DCM_ENABLE_RX_TX_NORM_NM, 9=DCM_ENABLE_RX_DISABLE_TX_NORM_NM, 10=DCM_DISABLE_RX_ENABLE_TX_NORM_NM, 11=DCM_DISABLE_RX_TX_NORM_NM}
      range raw 0..255
      implementation-data-type=uint8
    Dcm_Data16ByteType: category=ARRAY, sw-calibration-access=READ-ONLY
      element Dcm_Data16ByteTypeElement: array-size=16, array-size-semantics=FIXED-SIZE, implementation-data-type=uint8
    Dcm_DataElement_Data_VIN_Read_ArrayType: implementation-data-type=uint8
    Dcm_DataElement_Data_VIN_ReadType: category=ARRAY, sw-calibration-access=READ-ONLY
      element Dcm_DataElement_Data_VIN_ReadTypeElement: array-size=17, array-size-semantics=FIXED-SIZE, implementation-data-type=Dcm_DataElement_Data_VIN_Read_ArrayType
    Dcm_RequestDataArrayType: category=ARRAY, sw-calibration-access=READ-ONLY
      element Dcm_RequestDataArrayTypeElement: array-size=94, array-size-semantics=FIXED-SIZE, implementation-data-type=uint8
    Dcm_StartDataOut_Routine_CheckProgPreCond_Start_Out_ResDataArrayType: implementation-data-type=uint8
    Dcm_StartDataOut_Routine_CheckProgPreCond_Start_Out_ResDataType: category=ARRAY, sw-calibration-access=READ-ONLY
      element Dcm_StartDataOut_Routine_CheckProgPreCond_Start_Out_ResDataTypeElement: array-size=2, array-size-semantics=FIXED-SIZE, implementation-data-type=Dcm_StartDataOut_Routine_CheckProgPreCond_Start_Out_ResDataArrayType
    Dcm_StartDataOut_Routine_CheckSig_Start_Out_ResDataArrayType: implementation-data-type=uint8
    Dcm_StartDataOut_Routine_CheckSig_Start_Out_ResDataType: category=ARRAY, sw-calibration-access=READ-ONLY
      element Dcm_StartDataOut_Routine_CheckSig_Start_Out_ResDataTypeElement: array-size=1, array-size-semantics=FIXED-SIZE, implementation-data-type=Dcm_StartDataOut_Routine_CheckSig_Start_Out_ResDataArrayType
    Dcm_RequestDataOut_Routine_Static_Alignment_Execution_Start_Out_ResDataArrayType: implementation-data-type=uint8
    Dcm_RequestDataOut_Routine_Static_Alignment_Execution_Start_Out_ResDataType: category=ARRAY, sw-calibration-access=READ-ONLY
      element Dcm_RequestDataOut_Routine_Static_Alignment_Execution_Start_Out_ResDataTypeElement: array-size=3, array-size-semantics=FIXED-SIZE, implementation-data-type=Dcm_RequestDataOut_Routine_Static_Alignment_Execution_Start_Out_ResDataArrayType
    Dcm_RequestDataOut_Routine_Service_Alignment_Execution_Start_Out_ResDataArrayType: implementation-data-type=uint8
    Dcm_RequestDataOut_Routine_Service_Alignment_Execution_Start_Out_ResDataType: category=ARRAY, sw-calibration-access=READ-ONLY
      element Dcm_RequestDataOut_Routine_Service_Alignment_Execution_Start_Out_ResDataTypeElement: array-size=28, array-size-semantics=FIXED-SIZE, implementation-data-type=Dcm_RequestDataOut_Routine_Service_Alignment_Execution_Start_Out_ResDataArrayType
    Dcm_StartDataIn_Routine_Pin_Position_Lock_Start_In_ReqDataArrayType: implementation-data-type=uint8
    Dcm_StartDataIn_Routine_Pin_Position_Lock_Start_In_ReqDataType: category=ARRAY, sw-calibration-access=READ-ONLY
      element Dcm_StartDataIn_Routine_Pin_Position_Lock_Start_In_ReqDataTypeElement: array-size=1, array-size-semantics=FIXED-SIZE, implementation-data-type=Dcm_StartDataIn_Routine_Pin_Position_Lock_Start_In_ReqDataArrayType
    Dcm_StartDataOut_Routine_Pin_Position_Lock_Start_Out_ResDataArrayType: implementation-data-type=uint8
    Dcm_StartDataOut_Routine_Pin_Position_Lock_Start_Out_ResDataType: category=ARRAY, sw-calibration-access=READ-ONLY
      element Dcm_StartDataOut_Routine_Pin_Position_Lock_Start_Out_ResDataTypeElement: array-size=1, array-size-semantics=FIXED-SIZE, implementation-data-type=Dcm_StartDataOut_Routine_Pin_Position_Lock_Start_Out_ResDataArrayType
    Dcm_RequestDataOut_Routine_Pin_Position_Lock_Start_Out_ResDataArrayType: implementation-data-type=uint8
    Dcm_RequestDataOut_Routine_Pin_Position_Lock_Start_Out_ResDataType: category=ARRAY, sw-calibration-access=READ-ONLY
      element Dcm_RequestDataOut_Routine_Pin_Position_Lock_Start_Out_ResDataTypeElement: array-size=1, array-size-semantics=FIXED-SIZE, implementation-data-type=Dcm_RequestDataOut_Routine_Pin_Position_Lock_Start_Out_ResDataArrayType
    Dcm_StartDataIn_Routine_Pin_Position_Unlock_Start_In_ReqDataArrayType: implementation-data-type=uint8
    Dcm_StartDataIn_Routine_Pin_Position_Unlock_Start_In_ReqDataType: category=ARRAY, sw-calibration-access=READ-ONLY
      element Dcm_StartDataIn_Routine_Pin_Position_Unlock_Start_In_ReqDataTypeElement: array-size=1, array-size-semantics=FIXED-SIZE, implementation-data-type=Dcm_StartDataIn_Routine_Pin_Position_Unlock_Start_In_ReqDataArrayType
    Dcm_StartDataOut_Routine_Pin_Position_Unlock_Start_Out_ResDataArrayType: implementation-data-type=uint8
    Dcm_StartDataOut_Routine_Pin_Position_Unlock_Start_Out_ResDataType: category=ARRAY, sw-calibration-access=READ-ONLY
      element Dcm_StartDataOut_Routine_Pin_Position_Unlock_Start_Out_ResDataTypeElement: array-size=1, array-size-semantics=FIXED-SIZE, implementation-data-type=Dcm_StartDataOut_Routine_Pin_Position_Unlock_Start_Out_ResDataArrayType
    Dcm_RequestDataOut_Routine_Pin_Position_Unlock_Start_Out_ResDataArrayType: implementation-data-type=uint8
    Dcm_RequestDataOut_Routine_Pin_Position_Unlock_Start_Out_ResDataType: category=ARRAY, sw-calibration-access=READ-ONLY
      element Dcm_RequestDataOut_Routine_Pin_Position_Unlock_Start_Out_ResDataTypeElement: array-size=1, array-size-semantics=FIXED-SIZE, implementation-data-type=Dcm_RequestDataOut_Routine_Pin_Position_Unlock_Start_Out_ResDataArrayType
    Dcm_StartDataIn_Routine_EraseMem_Start_In_ReqDataArrayType: implementation-data-type=uint8
    Dcm_StartDataIn_Routine_EraseMem_Start_In_ReqDataType: category=ARRAY, sw-calibration-access=READ-ONLY
      element Dcm_StartDataIn_Routine_EraseMem_Start_In_ReqDataTypeElement: array-size=9, array-size-semantics=FIXED-SIZE, implementation-data-type=Dcm_StartDataIn_Routine_EraseMem_Start_In_ReqDataArrayType
    Dcm_StartDataOut_Routine_EraseMem_Start_Out_ResDataArrayType: implementation-data-type=uint8
    Dcm_StartDataOut_Routine_EraseMem_Start_Out_ResDataType: category=ARRAY, sw-calibration-access=READ-ONLY
      element Dcm_StartDataOut_Routine_EraseMem_Start_Out_ResDataTypeElement: array-size=1, array-size-semantics=FIXED-SIZE, implementation-data-type=Dcm_StartDataOut_Routine_EraseMem_Start_Out_ResDataArrayType
    Dcm_StartDataOut_Routine_CheckProgDep_Start_Out_ResDataArrayType: implementation-data-type=uint8
    Dcm_StartDataOut_Routine_CheckProgDep_Start_Out_ResDataType: category=ARRAY, sw-calibration-access=READ-ONLY
      element Dcm_StartDataOut_Routine_CheckProgDep_Start_Out_ResDataTypeElement: array-size=1, array-size-semantics=FIXED-SIZE, implementation-data-type=Dcm_StartDataOut_Routine_CheckProgDep_Start_Out_ResDataArrayType
    Dcm_DataElement_Data_ECUBuildDate_Read_ArrayType: implementation-data-type=uint8
    Dcm_DataElement_Data_ECUBuildDate_ReadType: category=ARRAY, sw-calibration-access=READ-ONLY
      element Dcm_DataElement_Data_ECUBuildDate_ReadTypeElement: array-size=4, array-size-semantics=FIXED-SIZE, implementation-data-type=Dcm_DataElement_Data_ECUBuildDate_Read_ArrayType
    Dcm_DataElement_Data_Static_Alignment_Engineering_Write_Configuration_Parameter_Write_ArrayType: implementation-data-type=uint8
    Dcm_DataElement_Data_Static_Alignment_Engineering_Write_Configuration_Parameter_WriteType: category=ARRAY, sw-calibration-access=READ-ONLY
      element Dcm_DataElement_Data_Static_Alignment_Engineering_Write_Configuration_Parameter_WriteTypeElement: array-size=6, array-size-semantics=FIXED-SIZE, implementation-data-type=Dcm_DataElement_Data_Static_Alignment_Engineering_Write_Configuration_Parameter_Write_ArrayType
    Dcm_DataElement_Data_CANDBMatrixVer_Read_ArrayType: implementation-data-type=uint8
    Dcm_DataElement_Data_CANDBMatrixVer_ReadType: category=ARRAY, sw-calibration-access=READ-ONLY
      element Dcm_DataElement_Data_CANDBMatrixVer_ReadTypeElement: array-size=2, array-size-semantics=FIXED-SIZE, implementation-data-type=Dcm_DataElement_Data_CANDBMatrixVer_Read_ArrayType
    Dcm_DataElement_Data_Service_Alignment_Engineering_Non_Configuration_Parameters_Read_ArrayType: implementation-data-type=uint8
    Dcm_DataElement_Data_Service_Alignment_Engineering_Non_Configuration_Parameters_ReadType: category=ARRAY, sw-calibration-access=READ-ONLY
      element Dcm_DataElement_Data_Service_Alignment_Engineering_Non_Configuration_Parameters_ReadTypeElement: array-size=14, array-size-semantics=FIXED-SIZE, implementation-data-type=Dcm_DataElement_Data_Service_Alignment_Engineering_Non_Configuration_Parameters_Read_ArrayType
    Dcm_DataElement_Data_Sensor_Availability_Flag_Read_ArrayType: implementation-data-type=uint8
    Dcm_DataElement_Data_Sensor_Availability_Flag_ReadType: category=ARRAY, sw-calibration-access=READ-ONLY
      element Dcm_DataElement_Data_Sensor_Availability_Flag_ReadTypeElement: array-size=1, array-size-semantics=FIXED-SIZE, implementation-data-type=Dcm_DataElement_Data_Sensor_Availability_Flag_Read_ArrayType
    Dcm_DataElement_Data_Read_Active_Fault_Table_Read_ArrayType: implementation-data-type=uint8
    Dcm_DataElement_Data_Read_Active_Fault_Table_ReadType: category=ARRAY, sw-calibration-access=READ-ONLY
      element Dcm_DataElement_Data_Read_Active_Fault_Table_ReadTypeElement: array-size=22, array-size-semantics=FIXED-SIZE, implementation-data-type=Dcm_DataElement_Data_Read_Active_Fault_Table_Read_ArrayType
    Dcm_DataElement_Data_Static_Alignment_Engineering_Non_Configuration_Parameters_Read_ArrayType: implementation-data-type=uint8
    Dcm_DataElement_Data_Static_Alignment_Engineering_Non_Configuration_Parameters_ReadType: category=ARRAY, sw-calibration-access=READ-ONLY
      element Dcm_DataElement_Data_Static_Alignment_Engineering_Non_Configuration_Parameters_ReadTypeElement: array-size=42, array-size-semantics=FIXED-SIZE, implementation-data-type=Dcm_DataElement_Data_Static_Alignment_Engineering_Non_Configuration_Parameters_Read_ArrayType
    Dcm_DataElement_Data_Dataset_Part_No_and_Revision_Read_ArrayType: implementation-data-type=uint8
    Dcm_DataElement_Data_Dataset_Part_No_and_Revision_ReadType: category=ARRAY, sw-calibration-access=READ-ONLY
      element Dcm_DataElement_Data_Dataset_Part_No_and_Revision_ReadTypeElement: array-size=12, array-size-semantics=FIXED-SIZE, implementation-data-type=Dcm_DataElement_Data_Dataset_Part_No_and_Revision_Read_ArrayType
    Dcm_DataElement_Data_HardwareNumber_Read_ArrayType: implementation-data-type=uint8
    Dcm_DataElement_Data_HardwareNumber_ReadType: category=ARRAY, sw-calibration-access=READ-ONLY
      element Dcm_DataElement_Data_HardwareNumber_ReadTypeElement: array-size=13, array-size-semantics=FIXED-SIZE, implementation-data-type=Dcm_DataElement_Data_HardwareNumber_Read_ArrayType
    Dcm_DataElement_Data_Vehicle_Variant_Read_ArrayType: implementation-data-type=uint8
    Dcm_DataElement_Data_Vehicle_Variant_ReadType: category=ARRAY, sw-calibration-access=READ-ONLY
      element Dcm_DataElement_Data_Vehicle_Variant_ReadTypeElement: array-size=1, array-size-semantics=FIXED-SIZE, implementation-data-type=Dcm_DataElement_Data_Vehicle_Variant_Read_ArrayType
    Dcm_DataElement_Data_Static_Alignment_Result_Parameters_Read_ArrayType: implementation-data-type=uint8
    Dcm_DataElement_Data_Static_Alignment_Result_Parameters_ReadType: category=ARRAY, sw-calibration-access=READ-ONLY
      element Dcm_DataElement_Data_Static_Alignment_Result_Parameters_ReadTypeElement: array-size=55, array-size-semantics=FIXED-SIZE, implementation-data-type=Dcm_DataElement_Data_Static_Alignment_Result_Parameters_Read_ArrayType
    Dcm_DataElement_Data_Base_Software_Version_number_Read_ArrayType: implementation-data-type=uint8
    Dcm_DataElement_Data_Base_Software_Version_number_ReadType: category=ARRAY, sw-calibration-access=READ-ONLY
      element Dcm_DataElement_Data_Base_Software_Version_number_ReadTypeElement: array-size=7, array-size-semantics=FIXED-SIZE, implementation-data-type=Dcm_DataElement_Data_Base_Software_Version_number_Read_ArrayType
    Dcm_DataElement_Data_VehicleSpeed_Read_ArrayType: implementation-data-type=uint8
    Dcm_DataElement_Data_VehicleSpeed_ReadType: category=ARRAY, sw-calibration-access=READ-ONLY
      element Dcm_DataElement_Data_VehicleSpeed_ReadTypeElement: array-size=2, array-size-semantics=FIXED-SIZE, implementation-data-type=Dcm_DataElement_Data_VehicleSpeed_Read_ArrayType
    Dcm_DataElement_Data_Software_Fingerprint_Read_ArrayType: implementation-data-type=uint8
    Dcm_DataElement_Data_Software_Fingerprint_ReadType: category=ARRAY, sw-calibration-access=READ-ONLY
      element Dcm_DataElement_Data_Software_Fingerprint_ReadTypeElement: array-size=4, array-size-semantics=FIXED-SIZE, implementation-data-type=Dcm_DataElement_Data_Software_Fingerprint_Read_ArrayType
    Dcm_DataElement_Data_Ego_Acceleration_Read_ArrayType: implementation-data-type=uint8
    Dcm_DataElement_Data_Ego_Acceleration_ReadType: category=ARRAY, sw-calibration-access=READ-ONLY
      element Dcm_DataElement_Data_Ego_Acceleration_ReadTypeElement: array-size=1, array-size-semantics=FIXED-SIZE, implementation-data-type=Dcm_DataElement_Data_Ego_Acceleration_Read_ArrayType
    Dcm_DataElement_Data_Static_Alignment_Engineering_Read_Parameters_Read_ArrayType: implementation-data-type=uint8
    Dcm_DataElement_Data_Static_Alignment_Engineering_Read_Parameters_ReadType: category=ARRAY, sw-calibration-access=READ-ONLY
      element Dcm_DataElement_Data_Static_Alignment_Engineering_Read_Parameters_ReadTypeElement: array-size=22, array-size-semantics=FIXED-SIZE, implementation-data-type=Dcm_DataElement_Data_Static_Alignment_Engineering_Read_Parameters_Read_ArrayType
    Dcm_DataElement_Data_BootloaderNumber_Read_ArrayType: implementation-data-type=uint8
    Dcm_DataElement_Data_BootloaderNumber_ReadType: category=ARRAY, sw-calibration-access=READ-ONLY
      element Dcm_DataElement_Data_BootloaderNumber_ReadTypeElement: array-size=12, array-size-semantics=FIXED-SIZE, implementation-data-type=Dcm_DataElement_Data_BootloaderNumber_Read_ArrayType
    Dcm_DataElement_Data_ECUVoltage_Read_ArrayType: implementation-data-type=uint8
    Dcm_DataElement_Data_ECUVoltage_ReadType: category=ARRAY, sw-calibration-access=READ-ONLY
      element Dcm_DataElement_Data_ECUVoltage_ReadTypeElement: array-size=2, array-size-semantics=FIXED-SIZE, implementation-data-type=Dcm_DataElement_Data_ECUVoltage_Read_ArrayType
    Dcm_DataElement_Data_Boot_App_Identification_DID_Read_ArrayType: implementation-data-type=uint8
    Dcm_DataElement_Data_Boot_App_Identification_DID_ReadType: category=ARRAY, sw-calibration-access=READ-ONLY
      element Dcm_DataElement_Data_Boot_App_Identification_DID_ReadTypeElement: array-size=1, array-size-semantics=FIXED-SIZE, implementation-data-type=Dcm_DataElement_Data_Boot_App_Identification_DID_Read_ArrayType
    Dcm_DataElement_Data_ActiveDiagnosticSessionDataIdentifier_Read_ArrayType: implementation-data-type=uint8
    Dcm_DataElement_Data_ActiveDiagnosticSessionDataIdentifier_ReadType: category=ARRAY, sw-calibration-access=READ-ONLY
      element Dcm_DataElement_Data_ActiveDiagnosticSessionDataIdentifier_ReadTypeElement: array-size=1, array-size-semantics=FIXED-SIZE, implementation-data-type=Dcm_DataElement_Data_ActiveDiagnosticSessionDataIdentifier_Read_ArrayType
    Dcm_DataElement_Data_Hardware_Version_number_Read_ArrayType: implementation-data-type=uint8
    Dcm_DataElement_Data_Hardware_Version_number_ReadType: category=ARRAY, sw-calibration-access=READ-ONLY
      element Dcm_DataElement_Data_Hardware_Version_number_ReadTypeElement: array-size=5, array-size-semantics=FIXED-SIZE, implementation-data-type=Dcm_DataElement_Data_Hardware_Version_number_Read_ArrayType
    Dcm_DataElement_Data_Manual_Alignment_Execution_Read_ArrayType: implementation-data-type=uint8
    Dcm_DataElement_Data_Manual_Alignment_Execution_ReadType: category=ARRAY, sw-calibration-access=READ-ONLY
      element Dcm_DataElement_Data_Manual_Alignment_Execution_ReadTypeElement: array-size=10, array-size-semantics=FIXED-SIZE, implementation-data-type=Dcm_DataElement_Data_Manual_Alignment_Execution_Read_ArrayType
    Dcm_DataElement_Data_SerialNumber_Read_ArrayType: implementation-data-type=uint8
    Dcm_DataElement_Data_SerialNumber_ReadType: category=ARRAY, sw-calibration-access=READ-ONLY
      element Dcm_DataElement_Data_SerialNumber_ReadTypeElement: array-size=16, array-size-semantics=FIXED-SIZE, implementation-data-type=Dcm_DataElement_Data_SerialNumber_Read_ArrayType
    Dcm_DataElement_Data_PCAN_DBC_Version_Read_ArrayType: implementation-data-type=uint8
    Dcm_DataElement_Data_PCAN_DBC_Version_ReadType: category=ARRAY, sw-calibration-access=READ-ONLY
      element Dcm_DataElement_Data_PCAN_DBC_Version_ReadTypeElement: array-size=2, array-size-semantics=FIXED-SIZE, implementation-data-type=Dcm_DataElement_Data_PCAN_DBC_Version_Read_ArrayType
    Dcm_DataElement_Data_Auto_Alignment_Status_Information_Read_ArrayType: implementation-data-type=uint8
    Dcm_DataElement_Data_Auto_Alignment_Status_Information_ReadType: category=ARRAY, sw-calibration-access=READ-ONLY
      element Dcm_DataElement_Data_Auto_Alignment_Status_Information_ReadTypeElement: array-size=93, array-size-semantics=FIXED-SIZE, implementation-data-type=Dcm_DataElement_Data_Auto_Alignment_Status_Information_Read_ArrayType
    Dcm_DataElement_Data_Service_Alignment_Result_Parameters_Read_ArrayType: implementation-data-type=uint8
    Dcm_DataElement_Data_Service_Alignment_Result_Parameters_ReadType: category=ARRAY, sw-calibration-access=READ-ONLY
      element Dcm_DataElement_Data_Service_Alignment_Result_Parameters_ReadTypeElement: array-size=87, array-size-semantics=FIXED-SIZE, implementation-data-type=Dcm_DataElement_Data_Service_Alignment_Result_Parameters_Read_ArrayType
    Dcm_DataElement_Data_SMC_Part_No_and_Revision_Read_ArrayType: implementation-data-type=uint8
    Dcm_DataElement_Data_SMC_Part_No_and_Revision_ReadType: category=ARRAY, sw-calibration-access=READ-ONLY
      element Dcm_DataElement_Data_SMC_Part_No_and_Revision_ReadTypeElement: array-size=12, array-size-semantics=FIXED-SIZE, implementation-data-type=Dcm_DataElement_Data_SMC_Part_No_and_Revision_Read_ArrayType
    Dcm_DataElement_Data_DateandTime_Read_ArrayType: implementation-data-type=uint8
    Dcm_DataElement_Data_DateandTime_ReadType: category=ARRAY, sw-calibration-access=READ-ONLY
      element Dcm_DataElement_Data_DateandTime_ReadTypeElement: array-size=7, array-size-semantics=FIXED-SIZE, implementation-data-type=Dcm_DataElement_Data_DateandTime_Read_ArrayType
    Dcm_DataElement_Data_SoftwareNumber_Read_ArrayType: implementation-data-type=uint8
    Dcm_DataElement_Data_SoftwareNumber_ReadType: category=ARRAY, sw-calibration-access=READ-ONLY
      element Dcm_DataElement_Data_SoftwareNumber_ReadTypeElement: array-size=14, array-size-semantics=FIXED-SIZE, implementation-data-type=Dcm_DataElement_Data_SoftwareNumber_Read_ArrayType
    Dcm_DataElement_Data_Pin_Position_Status_Read_ArrayType: implementation-data-type=uint8
    Dcm_DataElement_Data_Pin_Position_Status_ReadType: category=ARRAY, sw-calibration-access=READ-ONLY
      element Dcm_DataElement_Data_Pin_Position_Status_ReadTypeElement: array-size=2, array-size-semantics=FIXED-SIZE, implementation-data-type=Dcm_DataElement_Data_Pin_Position_Status_Read_ArrayType
    Dcm_Data96ByteType: category=ARRAY, sw-calibration-access=READ-ONLY
      element Dcm_Data96ByteTypeElement: array-size=96, array-size-semantics=FIXED-SIZE, implementation-data-type=uint8
    Dcm_SecLevelType: compu {0=DCM_SEC_LEV_LOCKED, 9=DCM_SEC_LEV_L9}, range raw 0..9, implementation-data-type=uint8
package /MICROSAR/Dcm_swc/ComponentTypes
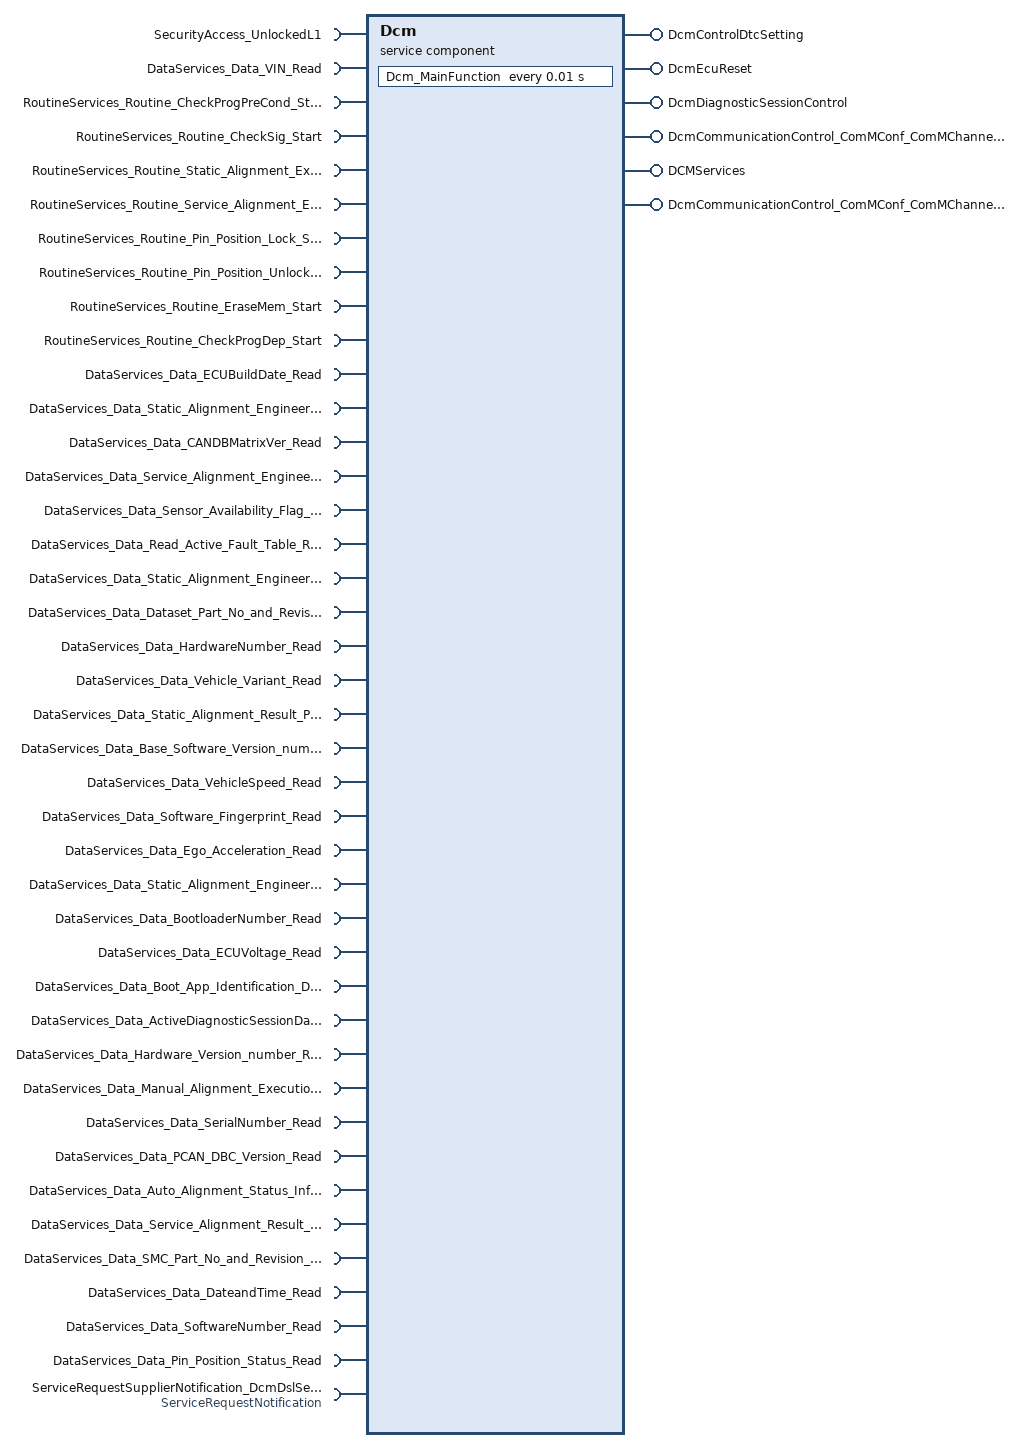
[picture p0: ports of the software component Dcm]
  service sw component type Dcm: category=SERVICE_COMPONENT
    5 x provide port:
      DcmControlDtcSetting: provided-interface=DcmControlDtcSetting
      DcmEcuReset: mode-switch-sender-com-spec{mode-group=DcmEcuReset, mode-switched-ack=timeout=0}, provided-interface=DcmEcuReset
      DcmDiagnosticSessionControl: provided-interface=DcmDiagnosticSessionControl
      DcmCommunicationControl_ComMConf_ComMChannel_CN_PCAN_RADAR_458ff0f1: provided-interface=DcmCommunicationControl_ComMConf_ComMChannel_CN_PCAN_RADAR_458ff0f1
      DCMServices: provided-interface=DCMServices
    41 x require port:
      SecurityAccess_UnlockedL1: required-interface=SecurityAccess_UnlockedL1
      DataServices_Data_VIN_Read: required-interface=DataServices_Data_VIN_Read
      RoutineServices_Routine_CheckProgPreCond_Start: required-interface=RoutineServices_Routine_CheckProgPreCond_Start
      RoutineServices_Routine_CheckSig_Start: required-interface=RoutineServices_Routine_CheckSig_Start
      RoutineServices_Routine_Static_Alignment_Execution_Start: required-interface=RoutineServices_Routine_Static_Alignment_Execution_Start
      RoutineServices_Routine_Service_Alignment_Execution_Start: required-interface=RoutineServices_Routine_Service_Alignment_Execution_Start
      RoutineServices_Routine_Pin_Position_Lock_Start: required-interface=RoutineServices_Routine_Pin_Position_Lock_Start
      RoutineServices_Routine_Pin_Position_Unlock_Start: required-interface=RoutineServices_Routine_Pin_Position_Unlock_Start
      RoutineServices_Routine_EraseMem_Start: required-interface=RoutineServices_Routine_EraseMem_Start
      RoutineServices_Routine_CheckProgDep_Start: required-interface=RoutineServices_Routine_CheckProgDep_Start
      DataServices_Data_ECUBuildDate_Read: required-interface=DataServices_Data_ECUBuildDate_Read
      DataServices_Data_Static_Alignment_Engineering_Write_Configuration_Parameter_Write: required-interface=DataServices_Data_Static_Alignment_Engineering_Write_Configuration_Parameter_Write
      DataServices_Data_CANDBMatrixVer_Read: required-interface=DataServices_Data_CANDBMatrixVer_Read
      DataServices_Data_Service_Alignment_Engineering_Non_Configuration_Parameters_Read: required-interface=DataServices_Data_Service_Alignment_Engineering_Non_Configuration_Parameters_Read
      DataServices_Data_Sensor_Availability_Flag_Read: required-interface=DataServices_Data_Sensor_Availability_Flag_Read
      DataServices_Data_Read_Active_Fault_Table_Read: required-interface=DataServices_Data_Read_Active_Fault_Table_Read
      DataServices_Data_Static_Alignment_Engineering_Non_Configuration_Parameters_Read: required-interface=DataServices_Data_Static_Alignment_Engineering_Non_Configuration_Parameters_Read
      DataServices_Data_Dataset_Part_No_and_Revision_Read: required-interface=DataServices_Data_Dataset_Part_No_and_Revision_Read
      DataServices_Data_HardwareNumber_Read: required-interface=DataServices_Data_HardwareNumber_Read
      DataServices_Data_Vehicle_Variant_Read: required-interface=DataServices_Data_Vehicle_Variant_Read
      DataServices_Data_Static_Alignment_Result_Parameters_Read: required-interface=DataServices_Data_Static_Alignment_Result_Parameters_Read
      DataServices_Data_Base_Software_Version_number_Read: required-interface=DataServices_Data_Base_Software_Version_number_Read
      DataServices_Data_VehicleSpeed_Read: required-interface=DataServices_Data_VehicleSpeed_Read
      DataServices_Data_Software_Fingerprint_Read: required-interface=DataServices_Data_Software_Fingerprint_Read
      DataServices_Data_Ego_Acceleration_Read: required-interface=DataServices_Data_Ego_Acceleration_Read
      DataServices_Data_Static_Alignment_Engineering_Read_Parameters_Read: required-interface=DataServices_Data_Static_Alignment_Engineering_Read_Parameters_Read
      DataServices_Data_BootloaderNumber_Read: required-interface=DataServices_Data_BootloaderNumber_Read
      DataServices_Data_ECUVoltage_Read: required-interface=DataServices_Data_ECUVoltage_Read
      DataServices_Data_Boot_App_Identification_DID_Read: required-interface=DataServices_Data_Boot_App_Identification_DID_Read
      DataServices_Data_ActiveDiagnosticSessionDataIdentifier_Read: required-interface=DataServices_Data_ActiveDiagnosticSessionDataIdentifier_Read
      DataServices_Data_Hardware_Version_number_Read: required-interface=DataServices_Data_Hardware_Version_number_Read
      DataServices_Data_Manual_Alignment_Execution_Read: required-interface=DataServices_Data_Manual_Alignment_Execution_Read
      DataServices_Data_SerialNumber_Read: required-interface=DataServices_Data_SerialNumber_Read
      DataServices_Data_PCAN_DBC_Version_Read: required-interface=DataServices_Data_PCAN_DBC_Version_Read
      DataServices_Data_Auto_Alignment_Status_Information_Read: required-interface=DataServices_Data_Auto_Alignment_Status_Information_Read
      DataServices_Data_Service_Alignment_Result_Parameters_Read: required-interface=DataServices_Data_Service_Alignment_Result_Parameters_Read
      DataServices_Data_SMC_Part_No_and_Revision_Read: required-interface=DataServices_Data_SMC_Part_No_and_Revision_Read
      DataServices_Data_DateandTime_Read: required-interface=DataServices_Data_DateandTime_Read
      DataServices_Data_SoftwareNumber_Read: required-interface=DataServices_Data_SoftwareNumber_Read
      DataServices_Data_Pin_Position_Status_Read: required-interface=DataServices_Data_Pin_Position_Status_Read
      ServiceRequestSupplierNotification_DcmDslServiceRequestSupplierNotification: required-interface=ServiceRequestNotification
    provide port DcmCommunicationControl_ComMConf_ComMChannel_CN_VCAN_RADAR_489180b6: provided-interface=DcmCommunicationControl_ComMConf_ComMChannel_CN_VCAN_RADAR_489180b6
    behavior DcmInternalBehavior: data-type-mapping=DcmMappingSet, handle-termination-and-restart=NO-SUPPORT, included-data-type-set=data-type=[Dcm_ConfirmationStatusType, Dcm_OpStatusType, Dcm_NegativeResponseCodeType, Dcm_ProtocolType, Dcm_RequestKindType, Dcm_SecLevelType, Dcm_SesCtrlType, Dcm_RequestDataArrayType, Dcm_ControlDtcSettingType, Dcm_EcuResetType, Dcm_DiagnosticSessionControlType, Dcm_CommunicationModeType]
      timing event Timer_Dcm_MainFunction: start-on-event=Dcm_MainFunction, period=0.01
      6 x operation invoked event:
        OpEventGetActiveProtocol_GetActiveProtocol_DCMServices: start-on-event=GetActiveProtocol, operation=DCMServices.GetActiveProtocol
        OpEventGetSesCtrlType_GetSesCtrlType_DCMServices: start-on-event=GetSesCtrlType, operation=DCMServices.GetSesCtrlType
        OpEventResetToDefaultSession_ResetToDefaultSession_DCMServices: start-on-event=ResetToDefaultSession, operation=DCMServices.ResetToDefaultSession
        OpEventGetSecurityLevel_GetSecurityLevel_DCMServices: start-on-event=GetSecurityLevel, operation=DCMServices.GetSecurityLevel
        OpEventSetActiveDiagnostic_SetActiveDiagnostic_DCMServices: start-on-event=SetActiveDiagnostic, operation=DCMServices.SetActiveDiagnostic
        OpEventGetRequestKind_GetRequestKind_DCMServices: start-on-event=GetRequestKind, operation=DCMServices.GetRequestKind
      port-api-options:
        enable-take-address=true, indirect-api=false, port=DcmControlDtcSetting
        enable-take-address=true, indirect-api=false, port=DcmEcuReset
        enable-take-address=true, indirect-api=false, port=DcmDiagnosticSessionControl
        enable-take-address=true, indirect-api=false, port=DcmCommunicationControl_ComMConf_ComMChannel_CN_PCAN_RADAR_458ff0f1
        enable-take-address=true, indirect-api=false, port=DCMServices
        enable-take-address=true, indirect-api=false, port=SecurityAccess_UnlockedL1
        enable-take-address=true, indirect-api=false, port=DataServices_Data_VIN_Read
        enable-take-address=true, indirect-api=false, port=RoutineServices_Routine_CheckProgPreCond_Start
        enable-take-address=true, indirect-api=false, port=RoutineServices_Routine_CheckSig_Start
        enable-take-address=true, indirect-api=false, port=RoutineServices_Routine_Static_Alignment_Execution_Start
        enable-take-address=true, indirect-api=false, port=RoutineServices_Routine_Service_Alignment_Execution_Start
        enable-take-address=true, indirect-api=false, port=RoutineServices_Routine_Pin_Position_Lock_Start
        enable-take-address=true, indirect-api=false, port=RoutineServices_Routine_Pin_Position_Unlock_Start
        enable-take-address=true, indirect-api=false, port=RoutineServices_Routine_EraseMem_Start
        enable-take-address=true, indirect-api=false, port=RoutineServices_Routine_CheckProgDep_Start
        enable-take-address=true, indirect-api=false, port=DataServices_Data_ECUBuildDate_Read
        enable-take-address=true, indirect-api=false, port=DataServices_Data_Static_Alignment_Engineering_Write_Configuration_Parameter_Write
        enable-take-address=true, indirect-api=false, port=DataServices_Data_CANDBMatrixVer_Read
        enable-take-address=true, indirect-api=false, port=DataServices_Data_Service_Alignment_Engineering_Non_Configuration_Parameters_Read
        enable-take-address=true, indirect-api=false, port=DataServices_Data_Sensor_Availability_Flag_Read
        enable-take-address=true, indirect-api=false, port=DataServices_Data_Read_Active_Fault_Table_Read
        enable-take-address=true, indirect-api=false, port=DataServices_Data_Static_Alignment_Engineering_Non_Configuration_Parameters_Read
        enable-take-address=true, indirect-api=false, port=DataServices_Data_Dataset_Part_No_and_Revision_Read
        enable-take-address=true, indirect-api=false, port=DataServices_Data_HardwareNumber_Read
        enable-take-address=true, indirect-api=false, port=DataServices_Data_Vehicle_Variant_Read
        enable-take-address=true, indirect-api=false, port=DataServices_Data_Static_Alignment_Result_Parameters_Read
        enable-take-address=true, indirect-api=false, port=DataServices_Data_Base_Software_Version_number_Read
        enable-take-address=true, indirect-api=false, port=DataServices_Data_VehicleSpeed_Read
        enable-take-address=true, indirect-api=false, port=DataServices_Data_Software_Fingerprint_Read
        enable-take-address=true, indirect-api=false, port=DataServices_Data_Ego_Acceleration_Read
        enable-take-address=true, indirect-api=false, port=DataServices_Data_Static_Alignment_Engineering_Read_Parameters_Read
        enable-take-address=true, indirect-api=false, port=DataServices_Data_BootloaderNumber_Read
        enable-take-address=true, indirect-api=false, port=DataServices_Data_ECUVoltage_Read
        enable-take-address=true, indirect-api=false, port=DataServices_Data_Boot_App_Identification_DID_Read
        enable-take-address=true, indirect-api=false, port=DataServices_Data_ActiveDiagnosticSessionDataIdentifier_Read
        enable-take-address=true, indirect-api=false, port=DataServices_Data_Hardware_Version_number_Read
        enable-take-address=true, indirect-api=false, port=DataServices_Data_Manual_Alignment_Execution_Read
        enable-take-address=true, indirect-api=false, port=DataServices_Data_SerialNumber_Read
        enable-take-address=true, indirect-api=false, port=DataServices_Data_PCAN_DBC_Version_Read
        enable-take-address=true, indirect-api=false, port=DataServices_Data_Auto_Alignment_Status_Information_Read
        enable-take-address=true, indirect-api=false, port=DataServices_Data_Service_Alignment_Result_Parameters_Read
        enable-take-address=true, indirect-api=false, port=DataServices_Data_SMC_Part_No_and_Revision_Read
        enable-take-address=true, indirect-api=false, port=DataServices_Data_DateandTime_Read
        enable-take-address=true, indirect-api=false, port=DataServices_Data_SoftwareNumber_Read
        enable-take-address=true, indirect-api=false, port=DataServices_Data_Pin_Position_Status_Read
        enable-take-address=true, indirect-api=false, port=ServiceRequestSupplierNotification_DcmDslServiceRequestSupplierNotification
        enable-take-address=true, indirect-api=false, port=DcmCommunicationControl_ComMConf_ComMChannel_CN_VCAN_RADAR_489180b6
      7 x runnable:
        Dcm_MainFunction
          5 x mode switch point:
            ModeSwitchPointDcm_MainFunction_DcmControlDtcSetting_DcmControlDtcSetting: mode-group=DcmControlDtcSetting.DcmControlDtcSetting
            ModeSwitchPointDcm_MainFunction_DcmEcuReset_DcmEcuReset: mode-group=DcmEcuReset.DcmEcuReset
            ModeSwitchPointDcm_MainFunction_DcmDiagnosticSessionControl_DcmDiagnosticSessionControl: mode-group=DcmDiagnosticSessionControl.DcmDiagnosticSessionControl
            ModeSwitchPointDcm_MainFunction_DcmCommunicationControl_ComMConf_ComMChannel_CN_PCAN_RADAR_458ff0f1_DcmCommunicationCon_c5a9e7aa: mode-group=DcmCommunicationControl_ComMConf_ComMChannel_CN_PCAN_RADAR_458ff0f1.DcmCommunicationControl_ComMConf_ComMChannel_CN_PCAN_RADAR_458ff0f1
            ModeSwitchPointDcm_MainFunction_DcmCommunicationControl_ComMConf_ComMChannel_CN_VCAN_RADAR_489180b6_DcmCommunicationCon_d128d441: mode-group=DcmCommunicationControl_ComMConf_ComMChannel_CN_VCAN_RADAR_489180b6.DcmCommunicationControl_ComMConf_ComMChannel_CN_VCAN_RADAR_489180b6
          84 x sync call, all with timeout=0:
            OpServerCallDcm_MainFunction_GetSeed_SecurityAccess_UnlockedL1: operation=SecurityAccess_UnlockedL1.GetSeed
            OpServerCallDcm_MainFunction_CompareKey_SecurityAccess_UnlockedL1: operation=SecurityAccess_UnlockedL1.CompareKey
            OpServerCallDcm_MainFunction_ReadData_DataServices_Data_VIN_Read: operation=DataServices_Data_VIN_Read.ReadData
            OpServerCallDcm_MainFunction_ConditionCheckRead_DataServices_Data_VIN_Read: operation=DataServices_Data_VIN_Read.ConditionCheckRead
            OpServerCallDcm_MainFunction_WriteData_DataServices_Data_VIN_Read: operation=DataServices_Data_VIN_Read.WriteData
            OpServerCallDcm_MainFunction_Start_RoutineServices_Routine_CheckProgPreCond_Start: operation=RoutineServices_Routine_CheckProgPreCond_Start.Start
            OpServerCallDcm_MainFunction_Start_RoutineServices_Routine_CheckSig_Start: operation=RoutineServices_Routine_CheckSig_Start.Start
            OpServerCallDcm_MainFunction_Start_RoutineServices_Routine_Static_Alignment_Execution_Start: operation=RoutineServices_Routine_Static_Alignment_Execution_Start.Start
            OpServerCallDcm_MainFunction_Stop_RoutineServices_Routine_Static_Alignment_Execution_Start: operation=RoutineServices_Routine_Static_Alignment_Execution_Start.Stop
            OpServerCallDcm_MainFunction_RequestResults_RoutineServices_Routine_Static_Alignment_Execution_Start: operation=RoutineServices_Routine_Static_Alignment_Execution_Start.RequestResults
            OpServerCallDcm_MainFunction_Start_RoutineServices_Routine_Service_Alignment_Execution_Start: operation=RoutineServices_Routine_Service_Alignment_Execution_Start.Start
            OpServerCallDcm_MainFunction_Stop_RoutineServices_Routine_Service_Alignment_Execution_Start: operation=RoutineServices_Routine_Service_Alignment_Execution_Start.Stop
            OpServerCallDcm_MainFunction_RequestResults_RoutineServices_Routine_Service_Alignment_Execution_Start: operation=RoutineServices_Routine_Service_Alignment_Execution_Start.RequestResults
            OpServerCallDcm_MainFunction_Start_RoutineServices_Routine_Pin_Position_Lock_Start: operation=RoutineServices_Routine_Pin_Position_Lock_Start.Start
            OpServerCallDcm_MainFunction_RequestResults_RoutineServices_Routine_Pin_Position_Lock_Start: operation=RoutineServices_Routine_Pin_Position_Lock_Start.RequestResults
            OpServerCallDcm_MainFunction_Start_RoutineServices_Routine_Pin_Position_Unlock_Start: operation=RoutineServices_Routine_Pin_Position_Unlock_Start.Start
            OpServerCallDcm_MainFunction_RequestResults_RoutineServices_Routine_Pin_Position_Unlock_Start: operation=RoutineServices_Routine_Pin_Position_Unlock_Start.RequestResults
            OpServerCallDcm_MainFunction_Start_RoutineServices_Routine_EraseMem_Start: operation=RoutineServices_Routine_EraseMem_Start.Start
            OpServerCallDcm_MainFunction_Start_RoutineServices_Routine_CheckProgDep_Start: operation=RoutineServices_Routine_CheckProgDep_Start.Start
            OpServerCallDcm_MainFunction_ReadData_DataServices_Data_ECUBuildDate_Read: operation=DataServices_Data_ECUBuildDate_Read.ReadData
            OpServerCallDcm_MainFunction_ConditionCheckRead_DataServices_Data_ECUBuildDate_Read: operation=DataServices_Data_ECUBuildDate_Read.ConditionCheckRead
            OpServerCallDcm_MainFunction_WriteData_DataServices_Data_Static_Alignment_Engineering_Write_Configuration_Parameter_Write: operation=DataServices_Data_Static_Alignment_Engineering_Write_Configuration_Parameter_Write.WriteData
            OpServerCallDcm_MainFunction_ReadData_DataServices_Data_CANDBMatrixVer_Read: operation=DataServices_Data_CANDBMatrixVer_Read.ReadData
            OpServerCallDcm_MainFunction_ConditionCheckRead_DataServices_Data_CANDBMatrixVer_Read: operation=DataServices_Data_CANDBMatrixVer_Read.ConditionCheckRead
            OpServerCallDcm_MainFunction_ReadData_DataServices_Data_Service_Alignment_Engineering_Non_Configuration_Parameters_Read: operation=DataServices_Data_Service_Alignment_Engineering_Non_Configuration_Parameters_Read.ReadData
            OpServerCallDcm_MainFunction_ConditionCheckRead_DataServices_Data_Service_Alignment_Engineering_Non_Configuration_Param_0e44c05d: operation=DataServices_Data_Service_Alignment_Engineering_Non_Configuration_Parameters_Read.ConditionCheckRead
            OpServerCallDcm_MainFunction_ReadData_DataServices_Data_Sensor_Availability_Flag_Read: operation=DataServices_Data_Sensor_Availability_Flag_Read.ReadData
            OpServerCallDcm_MainFunction_ConditionCheckRead_DataServices_Data_Sensor_Availability_Flag_Read: operation=DataServices_Data_Sensor_Availability_Flag_Read.ConditionCheckRead
            OpServerCallDcm_MainFunction_ReadData_DataServices_Data_Read_Active_Fault_Table_Read: operation=DataServices_Data_Read_Active_Fault_Table_Read.ReadData
            OpServerCallDcm_MainFunction_ConditionCheckRead_DataServices_Data_Read_Active_Fault_Table_Read: operation=DataServices_Data_Read_Active_Fault_Table_Read.ConditionCheckRead
            OpServerCallDcm_MainFunction_ReadData_DataServices_Data_Static_Alignment_Engineering_Non_Configuration_Parameters_Read: operation=DataServices_Data_Static_Alignment_Engineering_Non_Configuration_Parameters_Read.ReadData
            OpServerCallDcm_MainFunction_ConditionCheckRead_DataServices_Data_Static_Alignment_Engineering_Non_Configuration_Parameters_Read: operation=DataServices_Data_Static_Alignment_Engineering_Non_Configuration_Parameters_Read.ConditionCheckRead
            OpServerCallDcm_MainFunction_ReadData_DataServices_Data_Dataset_Part_No_and_Revision_Read: operation=DataServices_Data_Dataset_Part_No_and_Revision_Read.ReadData
            OpServerCallDcm_MainFunction_ConditionCheckRead_DataServices_Data_Dataset_Part_No_and_Revision_Read: operation=DataServices_Data_Dataset_Part_No_and_Revision_Read.ConditionCheckRead
            OpServerCallDcm_MainFunction_ReadData_DataServices_Data_HardwareNumber_Read: operation=DataServices_Data_HardwareNumber_Read.ReadData
            OpServerCallDcm_MainFunction_ConditionCheckRead_DataServices_Data_HardwareNumber_Read: operation=DataServices_Data_HardwareNumber_Read.ConditionCheckRead
            OpServerCallDcm_MainFunction_ReadData_DataServices_Data_Vehicle_Variant_Read: operation=DataServices_Data_Vehicle_Variant_Read.ReadData
            OpServerCallDcm_MainFunction_ConditionCheckRead_DataServices_Data_Vehicle_Variant_Read: operation=DataServices_Data_Vehicle_Variant_Read.ConditionCheckRead
            OpServerCallDcm_MainFunction_ReadData_DataServices_Data_Static_Alignment_Result_Parameters_Read: operation=DataServices_Data_Static_Alignment_Result_Parameters_Read.ReadData
            OpServerCallDcm_MainFunction_ConditionCheckRead_DataServices_Data_Static_Alignment_Result_Parameters_Read: operation=DataServices_Data_Static_Alignment_Result_Parameters_Read.ConditionCheckRead
            OpServerCallDcm_MainFunction_ReadData_DataServices_Data_Base_Software_Version_number_Read: operation=DataServices_Data_Base_Software_Version_number_Read.ReadData
            OpServerCallDcm_MainFunction_ConditionCheckRead_DataServices_Data_Base_Software_Version_number_Read: operation=DataServices_Data_Base_Software_Version_number_Read.ConditionCheckRead
            OpServerCallDcm_MainFunction_ReadData_DataServices_Data_VehicleSpeed_Read: operation=DataServices_Data_VehicleSpeed_Read.ReadData
            OpServerCallDcm_MainFunction_ConditionCheckRead_DataServices_Data_VehicleSpeed_Read: operation=DataServices_Data_VehicleSpeed_Read.ConditionCheckRead
            OpServerCallDcm_MainFunction_ReadData_DataServices_Data_Software_Fingerprint_Read: operation=DataServices_Data_Software_Fingerprint_Read.ReadData
            OpServerCallDcm_MainFunction_ConditionCheckRead_DataServices_Data_Software_Fingerprint_Read: operation=DataServices_Data_Software_Fingerprint_Read.ConditionCheckRead
            OpServerCallDcm_MainFunction_WriteData_DataServices_Data_Software_Fingerprint_Read: operation=DataServices_Data_Software_Fingerprint_Read.WriteData
            OpServerCallDcm_MainFunction_ReadData_DataServices_Data_Ego_Acceleration_Read: operation=DataServices_Data_Ego_Acceleration_Read.ReadData
            OpServerCallDcm_MainFunction_ConditionCheckRead_DataServices_Data_Ego_Acceleration_Read: operation=DataServices_Data_Ego_Acceleration_Read.ConditionCheckRead
            OpServerCallDcm_MainFunction_ReadData_DataServices_Data_Static_Alignment_Engineering_Read_Parameters_Read: operation=DataServices_Data_Static_Alignment_Engineering_Read_Parameters_Read.ReadData
            OpServerCallDcm_MainFunction_ConditionCheckRead_DataServices_Data_Static_Alignment_Engineering_Read_Parameters_Read: operation=DataServices_Data_Static_Alignment_Engineering_Read_Parameters_Read.ConditionCheckRead
            OpServerCallDcm_MainFunction_ReadData_DataServices_Data_BootloaderNumber_Read: operation=DataServices_Data_BootloaderNumber_Read.ReadData
            OpServerCallDcm_MainFunction_ConditionCheckRead_DataServices_Data_BootloaderNumber_Read: operation=DataServices_Data_BootloaderNumber_Read.ConditionCheckRead
            OpServerCallDcm_MainFunction_ReadData_DataServices_Data_ECUVoltage_Read: operation=DataServices_Data_ECUVoltage_Read.ReadData
            OpServerCallDcm_MainFunction_ConditionCheckRead_DataServices_Data_ECUVoltage_Read: operation=DataServices_Data_ECUVoltage_Read.ConditionCheckRead
            OpServerCallDcm_MainFunction_ReadData_DataServices_Data_Boot_App_Identification_DID_Read: operation=DataServices_Data_Boot_App_Identification_DID_Read.ReadData
            OpServerCallDcm_MainFunction_ConditionCheckRead_DataServices_Data_Boot_App_Identification_DID_Read: operation=DataServices_Data_Boot_App_Identification_DID_Read.ConditionCheckRead
            OpServerCallDcm_MainFunction_ReadData_DataServices_Data_ActiveDiagnosticSessionDataIdentifier_Read: operation=DataServices_Data_ActiveDiagnosticSessionDataIdentifier_Read.ReadData
            OpServerCallDcm_MainFunction_ConditionCheckRead_DataServices_Data_ActiveDiagnosticSessionDataIdentifier_Read: operation=DataServices_Data_ActiveDiagnosticSessionDataIdentifier_Read.ConditionCheckRead
            OpServerCallDcm_MainFunction_ReadData_DataServices_Data_Hardware_Version_number_Read: operation=DataServices_Data_Hardware_Version_number_Read.ReadData
            OpServerCallDcm_MainFunction_ConditionCheckRead_DataServices_Data_Hardware_Version_number_Read: operation=DataServices_Data_Hardware_Version_number_Read.ConditionCheckRead
            OpServerCallDcm_MainFunction_ReadData_DataServices_Data_Manual_Alignment_Execution_Read: operation=DataServices_Data_Manual_Alignment_Execution_Read.ReadData
            OpServerCallDcm_MainFunction_ConditionCheckRead_DataServices_Data_Manual_Alignment_Execution_Read: operation=DataServices_Data_Manual_Alignment_Execution_Read.ConditionCheckRead
            OpServerCallDcm_MainFunction_WriteData_DataServices_Data_Manual_Alignment_Execution_Read: operation=DataServices_Data_Manual_Alignment_Execution_Read.WriteData
            OpServerCallDcm_MainFunction_ReadData_DataServices_Data_SerialNumber_Read: operation=DataServices_Data_SerialNumber_Read.ReadData
            OpServerCallDcm_MainFunction_ConditionCheckRead_DataServices_Data_SerialNumber_Read: operation=DataServices_Data_SerialNumber_Read.ConditionCheckRead
            OpServerCallDcm_MainFunction_ReadData_DataServices_Data_PCAN_DBC_Version_Read: operation=DataServices_Data_PCAN_DBC_Version_Read.ReadData
            OpServerCallDcm_MainFunction_ConditionCheckRead_DataServices_Data_PCAN_DBC_Version_Read: operation=DataServices_Data_PCAN_DBC_Version_Read.ConditionCheckRead
            OpServerCallDcm_MainFunction_ReadData_DataServices_Data_Auto_Alignment_Status_Information_Read: operation=DataServices_Data_Auto_Alignment_Status_Information_Read.ReadData
            OpServerCallDcm_MainFunction_ConditionCheckRead_DataServices_Data_Auto_Alignment_Status_Information_Read: operation=DataServices_Data_Auto_Alignment_Status_Information_Read.ConditionCheckRead
            OpServerCallDcm_MainFunction_ReadData_DataServices_Data_Service_Alignment_Result_Parameters_Read: operation=DataServices_Data_Service_Alignment_Result_Parameters_Read.ReadData
            OpServerCallDcm_MainFunction_ConditionCheckRead_DataServices_Data_Service_Alignment_Result_Parameters_Read: operation=DataServices_Data_Service_Alignment_Result_Parameters_Read.ConditionCheckRead
            OpServerCallDcm_MainFunction_ReadData_DataServices_Data_SMC_Part_No_and_Revision_Read: operation=DataServices_Data_SMC_Part_No_and_Revision_Read.ReadData
            OpServerCallDcm_MainFunction_ConditionCheckRead_DataServices_Data_SMC_Part_No_and_Revision_Read: operation=DataServices_Data_SMC_Part_No_and_Revision_Read.ConditionCheckRead
            OpServerCallDcm_MainFunction_ReadData_DataServices_Data_DateandTime_Read: operation=DataServices_Data_DateandTime_Read.ReadData
            OpServerCallDcm_MainFunction_ConditionCheckRead_DataServices_Data_DateandTime_Read: operation=DataServices_Data_DateandTime_Read.ConditionCheckRead
            OpServerCallDcm_MainFunction_ReadData_DataServices_Data_SoftwareNumber_Read: operation=DataServices_Data_SoftwareNumber_Read.ReadData
            OpServerCallDcm_MainFunction_ConditionCheckRead_DataServices_Data_SoftwareNumber_Read: operation=DataServices_Data_SoftwareNumber_Read.ConditionCheckRead
            OpServerCallDcm_MainFunction_ReadData_DataServices_Data_Pin_Position_Status_Read: operation=DataServices_Data_Pin_Position_Status_Read.ReadData
            OpServerCallDcm_MainFunction_ConditionCheckRead_DataServices_Data_Pin_Position_Status_Read: operation=DataServices_Data_Pin_Position_Status_Read.ConditionCheckRead
            OpServerCallDcm_MainFunction_Indication_ServiceRequestSupplierNotification_DcmDslServiceRequestSupplierNotification: operation=ServiceRequestSupplierNotification_DcmDslServiceRequestSupplierNotification.Indication
            OpServerCallDcm_MainFunction_Confirmation_ServiceRequestSupplierNotification_DcmDslServiceRequestSupplierNotification: operation=ServiceRequestSupplierNotification_DcmDslServiceRequestSupplierNotification.Confirmation
            OpServerCallDcm_MainFunction_GetSecurityAttemptCounter_SecurityAccess_UnlockedL1: operation=SecurityAccess_UnlockedL1.GetSecurityAttemptCounter
            OpServerCallDcm_MainFunction_SetSecurityAttemptCounter_SecurityAccess_UnlockedL1: operation=SecurityAccess_UnlockedL1.SetSecurityAttemptCounter
        GetActiveProtocol: can-be-invoked-concurrently=true, symbol=Dcm_GetActiveProtocol
        GetSesCtrlType: can-be-invoked-concurrently=true, symbol=Dcm_GetSesCtrlType
        ResetToDefaultSession: can-be-invoked-concurrently=true, symbol=Dcm_ResetToDefaultSession
        GetSecurityLevel: can-be-invoked-concurrently=true, symbol=Dcm_GetSecurityLevel
        SetActiveDiagnostic: can-be-invoked-concurrently=true, symbol=Dcm_SetActiveDiagnostic
        GetRequestKind: can-be-invoked-concurrently=true, symbol=Dcm_GetRequestKind
  swc implementation DcmImplementation: programming-language=C, behavior=DcmInternalBehavior
    resource consumption DcmResourceConsumption
      5 x memory section:
        Dcm_CODE: sw-addrmethod=CODE, symbol=CODE
        Dcm_CONST_UNSPECIFIED: alignment=UNSPECIFIED, sw-addrmethod=CONST, symbol=CONST_UNSPECIFIED
        Dcm_VAR_NOINIT_UNSPECIFIED: alignment=UNSPECIFIED, sw-addrmethod=VAR_NO_INIT, symbol=VAR_NOINIT_UNSPECIFIED
        Dcm_VAR_INIT_UNSPECIFIED: alignment=UNSPECIFIED, sw-addrmethod=VAR_INIT, symbol=VAR_INIT_UNSPECIFIED
        Dcm_VAR_ZERO_INIT_UNSPECIFIED: alignment=UNSPECIFIED, sw-addrmethod=VAR_CLEARED, symbol=VAR_ZERO_INIT_UNSPECIFIED
